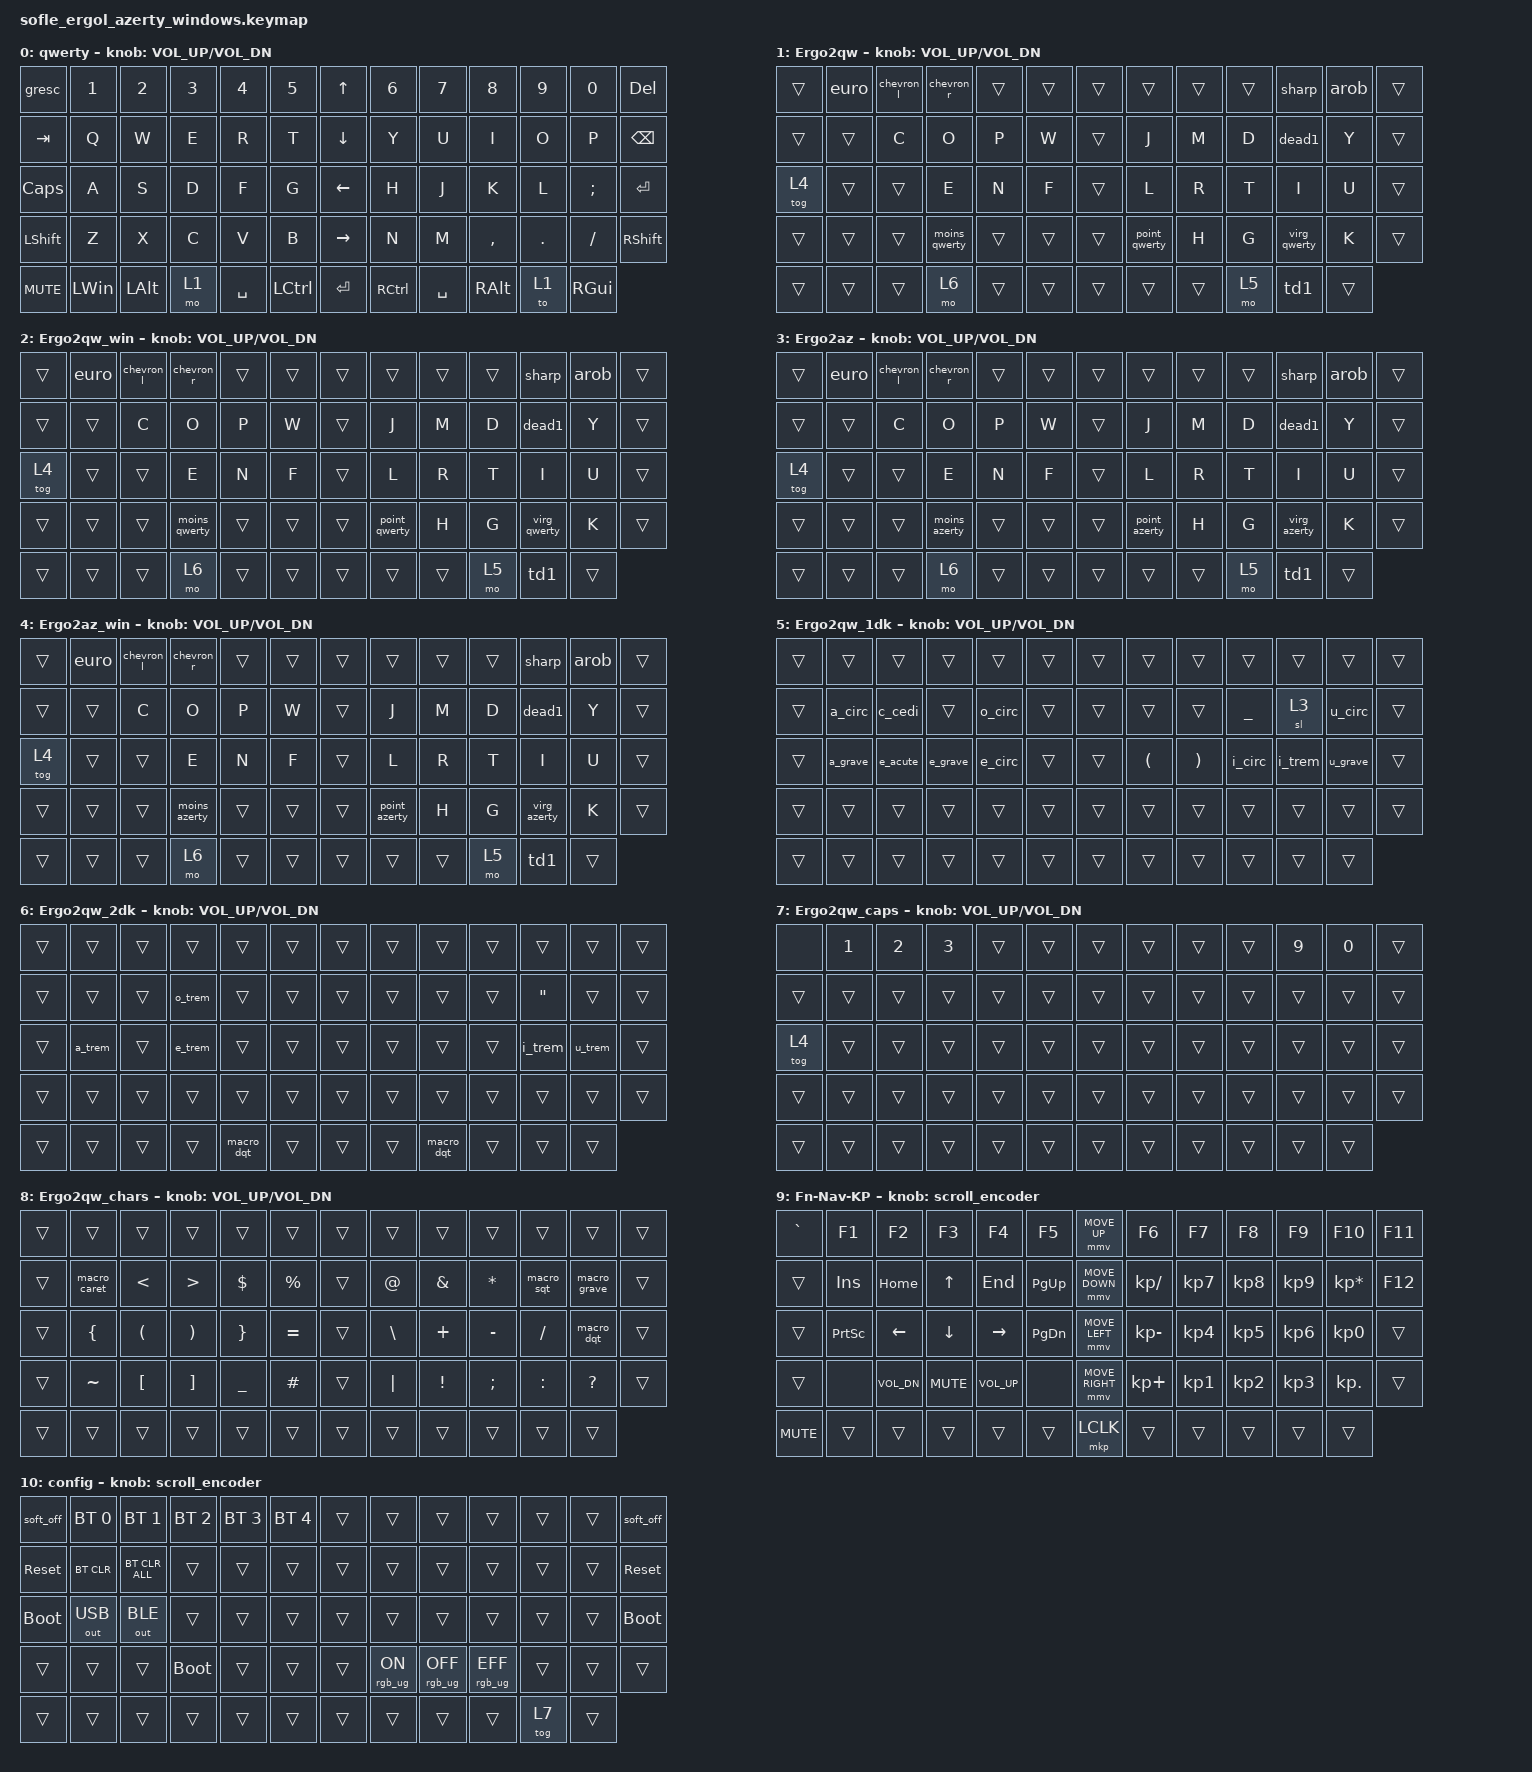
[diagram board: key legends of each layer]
#define ZMK_POINTING_DEFAULT_MOVE_VAL 1200  // 600
#define ZMK_POINTING_DEFAULT_SCRL_VAL 25    // 10

#include <input/processors.dtsi>
#include <zephyr/dt-bindings/input/input-event-codes.h>
#include <behaviors.dtsi>
#include <dt-bindings/zmk/bt.h>
#include <dt-bindings/zmk/keys.h>
#include <dt-bindings/zmk/outputs.h>
#include <dt-bindings/zmk/pointing.h>
#include <dt-bindings/zmk/rgb.h>

&mmv_input_listener { input-processors = <&zip_xy_scaler 2 1>; };

&msc_input_listener { input-processors = <&zip_scroll_scaler 2 1>; };

&msc {
    acceleration-exponent = <1>;      // 0
    time-to-max-speed-ms = <100>;       // 300
    delay-ms = <0>;                   // 0
};

&mmv {
    time-to-max-speed-ms = <500>;
    acceleration-exponent = <1>;
    trigger-period-ms = <16>;
};

/ {
    scroll_encoder: scroll_encoder {
        compatible = "zmk,behavior-sensor-rotate";
        #sensor-binding-cells = <0>;
        bindings = <&msc SCRL_DOWN>, <&msc SCRL_UP>;

        tap-ms = <100>;
    };

    macros {
        /////////////////////////////////////////////////////////////////////////////
        // Rangée 1                                                                //
        /////////////////////////////////////////////////////////////////////////////

        // ESC : QWERTY, AZERTY : ESC
        // ` : QWERTY : GRAVE
        // ` : AZERTY : BSLH SPACE
        macro_grave_azerty: macro_grave_azerty {
            compatible = "zmk,behavior-macro";
            #binding-cells = <0>;
            bindings
                = <&macro_tap &kp BSLH &kp SPACE>
                ;
        };
        // TRANS
        // TRANS
        // TRANS
        // TRANS

        ////// Normal //////
        // 1 : QWERTY : N1
        // 1 : AZERTY : LS(N1)
        ////// Shift //////
        // € : QWERTY : RA(N5)
        // € : AZERTY : RA(E) 
        ////// 1DK //////
        // „ : QWERTY, AZERTY : U+201E : Alt(0132) : DOUBLE LOW-9 QUOTATION MARK
        macro_dqt_low: macro_double_quote_low {
            compatible = "zmk,behavior-macro";
            #binding-cells = <0>;
            bindings
                = <&macro_press &kp L_CTL &kp L_SHIFT>
                , <&macro_tap &kp U &kp N2 &kp N0 &kp N1 &kp E &kp SPACE>
                , <&macro_release &kp L_CTL &kp L_SHIFT>
                ;
        };
        macro_dqt_low_win: macro_double_quote_low_win {
            compatible = "zmk,behavior-macro";
            #binding-cells = <0>;
            bindings
                = <&macro_press &kp L_ALT>
                , <&macro_tap &kp N0 &kp N1 &kp N3 &kp N2>
                , <&macro_release &kp L_ALT>
                ;
        };
        ////// 1DK Shift //////
        // NONE
        ////// Symboles //////
        // ₁ : QWERTY, AZERTY : U+2081 : SUBSCRIPT ONE
        macro_sub_1: macro_subscript_1 {
            compatible = "zmk,behavior-macro";
            #binding-cells = <0>;
            bindings
                = <&macro_press &kp L_CTL &kp L_SHIFT>
                , <&macro_tap &kp U &kp N2 &kp N0 &kp N8 &kp N1 &kp SPACE>
                , <&macro_release &kp L_CTL &kp L_SHIFT>
                ;
        };
        // ₁ : NO macro_sub_1_win : NONE
        ////// Symboles Shift //////
        // ¹ : QWERTY, AZERTY : U+00B9 : Alt(0185) : SUPERSCRIPT ONE
        macro_sup_1: macro_superscript_1 {
            compatible = "zmk,behavior-macro";
            #binding-cells = <0>;
            bindings
                = <&macro_press &kp L_CTL &kp L_SHIFT>
                , <&macro_tap &kp U &kp N0 &kp N0 &kp B &kp N9 &kp SPACE>
                , <&macro_release &kp L_CTL &kp L_SHIFT>
                ;
        };
        macro_sup_1_win: macro_superscript_1_win {
            compatible = "zmk,behavior-macro";
            #binding-cells = <0>;
            bindings
                = <&macro_press &kp L_ALT>
                , <&macro_tap &kp N0 &kp N1 &kp N8 &kp N5>
                , <&macro_release &kp L_ALT>
                ;
        };

        ////// Normal //////
        // 2 : QWERTY : N2
        // 2 : AZERTY : LS(N2)
        ////// Shift //////
        // « : QWERTY, AZERTY : U+00AB : Alt(0171) : LEFT-POINTING DOUBLE ANGLE QUOTATION MARK {left guillemet; chevrons (in typography)}
        macro_chevron_l: macro_chevron_left {
            compatible = "zmk,behavior-macro";
            #binding-cells = <0>;
            bindings
                = <&macro_press &kp L_CTL &kp L_SHIFT>
                , <&macro_tap &kp U &kp N0 &kp N0 &kp A &kp B &kp SPACE>
                , <&macro_release &kp L_CTL &kp L_SHIFT>
                ;
        };
        macro_chevron_l_win: macro_chevron_left_win {
            compatible = "zmk,behavior-macro";
            #binding-cells = <0>;
            bindings
                = <&macro_press &kp L_ALT>
                , <&macro_tap &kp N0 &kp N1 &kp N7 &kp N1>
                , <&macro_release &kp L_ALT>
                ;
        };
        ////// 1DK //////
        // “ : QWERTY, AZERTY : U+201C : Alt(0147) : LEFT DOUBLE QUOTATION MARK {double turned comma quotation mark}
        macro_dqm_l: macro_d_quot_mark_left {
            compatible = "zmk,behavior-macro";
            #binding-cells = <0>;
            bindings
                = <&macro_press &kp L_CTL &kp L_SHIFT>
                , <&macro_tap &kp U &kp N2 &kp N0 &kp N1 &kp C &kp SPACE>
                , <&macro_release &kp L_CTL &kp L_SHIFT>
                ;
        };
        macro_dqm_l_win: macro_d_quot_mark_left_win {
            compatible = "zmk,behavior-macro";
            #binding-cells = <0>;
            bindings
                = <&macro_press &kp L_ALT>
                , <&macro_tap &kp N0 &kp N1 &kp N4 &kp N7>
                , <&macro_release &kp L_ALT>
                ;
        };
        ////// 1DK Shift //////
        // ‘ : QWERTY, AZERTY : U+2018 : Alt(0145) : LEFT SINGLE QUOTATION MARK {single turned comma quotation mark}
        macro_sqm_l: macro_s_quot_mark_left {
            compatible = "zmk,behavior-macro";
            #binding-cells = <0>;
            bindings
                = <&macro_press &kp L_CTL &kp L_SHIFT>
                , <&macro_tap &kp U &kp N2 &kp N0 &kp N1 &kp N8 &kp SPACE>
                , <&macro_release &kp L_CTL &kp L_SHIFT>
                ;
        };
        macro_sqm_l_win: macro_s_quot_mark_left_win {
            compatible = "zmk,behavior-macro";
            #binding-cells = <0>;
            bindings
                = <&macro_press &kp L_ALT>
                , <&macro_tap &kp N0 &kp N1 &kp N4 &kp N5>
                , <&macro_release &kp L_ALT>
                ;
        };
        ////// Symboles //////
        // ₂ : QWERTY, AZERTY : U+2082 : SUBSCRIPT TWO
        macro_sub_2: macro_subscript_2 {
            compatible = "zmk,behavior-macro";
            #binding-cells = <0>;
            bindings
                = <&macro_press &kp L_CTL &kp L_SHIFT>
                , <&macro_tap &kp U &kp N2 &kp N0 &kp N8 &kp N2 &kp SPACE>
                , <&macro_release &kp L_CTL &kp L_SHIFT>
                ;
        };
        // ₂ : NO macro_sub_2_win : NONE
        ////// Symboles Shift //////
        // ² : QWERTY: RA(N2)
        // ² : AZERTY : GRAVE
    
        ////// Normal //////
        // 3 : QWERTY : N3
        // 3 : AZERTY : LS(N3)
        ////// Shift //////
        // » : QWERTY, AZERTY : U+00BB : Alt(0187) : RIGHT-POINTING DOUBLE ANGLE QUOTATION MARK {right guillemet}
        macro_chevron_r: macro_chevron_right {
            compatible = "zmk,behavior-macro";
            #binding-cells = <0>;
            bindings
                = <&macro_press &kp L_CTL &kp L_SHIFT>
                , <&macro_tap &kp U &kp N0 &kp N0 &kp B &kp B &kp SPACE>
                , <&macro_release &kp L_CTL &kp L_SHIFT>
                ;
        };
        macro_chevron_r_win: macro_chevron_right_win {
            compatible = "zmk,behavior-macro";
            #binding-cells = <0>;
            bindings
                = <&macro_press &kp L_ALT>
                , <&macro_tap &kp N0 &kp N1 &kp N8 &kp N7>
                , <&macro_release &kp L_ALT>
                ;
        };
        ////// 1DK //////
        // ” : QWERTY, AZERTY : U+201D : Alt(0148) : RIGHT DOUBLE QUOTATION MARK {double comma quotation mark}
        macro_dqm_r: macro_d_quot_mark_right {
            compatible = "zmk,behavior-macro";
            #binding-cells = <0>;
            bindings
                = <&macro_press &kp L_CTL &kp L_SHIFT>
                , <&macro_tap &kp U &kp N2 &kp N0 &kp N1 &kp D &kp SPACE>
                , <&macro_release &kp L_CTL &kp L_SHIFT>
                ;
        };
        macro_dqm_r_win: macro_d_quot_mark_right_win {
            compatible = "zmk,behavior-macro";
            #binding-cells = <0>;
            bindings
                = <&macro_press &kp L_ALT>
                , <&macro_tap &kp N0 &kp N1 &kp N4 &kp N8>
                , <&macro_release &kp L_ALT>
                ;
        };
        ////// 1DK Shift //////
        // ’ : QWERTY, AZERTY : U+2019 : Alt(0146) : RIGHT SINGLE QUOTATION MARK {single comma quotation mark}
        macro_sqm_r: macro_s_quot_mark_right {
            compatible = "zmk,behavior-macro";
            #binding-cells = <0>;
            bindings
                = <&macro_press &kp L_CTL &kp L_SHIFT>
                , <&macro_tap &kp U &kp N2 &kp N0 &kp N1 &kp N9 &kp SPACE>
                , <&macro_release &kp L_CTL &kp L_SHIFT>
                ;
        };
        macro_sqm_r_win: macro_s_quot_mark_right_win {
            compatible = "zmk,behavior-macro";
            #binding-cells = <0>;
            bindings
                = <&macro_press &kp L_ALT>
                , <&macro_tap &kp N0 &kp N1 &kp N4 &kp N6>
                , <&macro_release &kp L_ALT>
                ;
        };
        ////// Symboles //////
        // ₃ : QWERTY, AZERTY : U+2083 : SUBSCRIPT THREE
        macro_sub_3: macro_subscript_3 {
            compatible = "zmk,behavior-macro";
            #binding-cells = <0>;
            bindings
                = <&macro_press &kp L_CTL &kp L_SHIFT>
                , <&macro_tap &kp U &kp N2 &kp N0 &kp N8 &kp N3 &kp SPACE>
                , <&macro_release &kp L_CTL &kp L_SHIFT>
                ;
        };
        // ₃ : NO macro_sub_3_win : NONE
        ////// Symboles Shift //////
        // ³ : LS(GRAVE)
        // ² : RA(N3)
        

        ////// Normal //////
        // 4 : QWERTY : N4
        // 4 : AZERTY : LS(N4)
        ////// Shift //////
        // $ : QWERTY : DOLLAR
        // $ : AZERTY : RBKT
        ////// 1DK //////
        // ¢ : QWERTY, AZERTY : U+00A2 : Alt(0162) : CENT SIGN
        macro_cent: macro_cent {
            compatible = "zmk,behavior-macro";
            #binding-cells = <0>;
            bindings
                = <&macro_press &kp L_CTL &kp L_SHIFT>
                , <&macro_tap &kp U &kp N0 &kp N0 &kp A &kp N2 &kp SPACE>
                , <&macro_release &kp L_CTL &kp L_SHIFT>
                ;
        }; 
        macro_cent_win: macro_cent_win {
            compatible = "zmk,behavior-macro";
            #binding-cells = <0>;
            bindings
                = <&macro_press &kp L_ALT>
                , <&macro_tap &kp N0 &kp N1 &kp N6 &kp N2>
                , <&macro_release &kp L_ALT>
                ;
        }; 
        ////// 1DK Shift //////
        // NONE
        ////// Symboles //////
        // ₄ : QWERTY, AZERTY : U+2084 : SUBSCRIPT FOUR
        macro_sub_4: macro_subscript_4 {
            compatible = "zmk,behavior-macro";
            #binding-cells = <0>;
            bindings
                = <&macro_press &kp L_CTL &kp L_SHIFT>
                , <&macro_tap &kp U &kp N2 &kp N0 &kp N8 &kp N4 &kp SPACE>
                , <&macro_release &kp L_CTL &kp L_SHIFT>
                ;
        };
        // ₄ : NO macro_sub_4_win : NONE
        ////// Symboles Shift //////
        // ⁴ : QWERTY, AZERTY : U+2074 : SUPERSCRIPT FOUR
        macro_sup_4: macro_superscript_4 {
            compatible = "zmk,behavior-macro";
            #binding-cells = <0>;
            bindings
                = <&macro_press &kp L_CTL &kp L_SHIFT>
                , <&macro_tap &kp U &kp N2 &kp N0 &kp N7 &kp N4 &kp SPACE>
                , <&macro_release &kp L_CTL &kp L_SHIFT>
                ;
        };
        // ⁴ : NO macro_sup_4_win : NONE


        ////// Normal //////
        // 5 : QWERTY : N5
        // 5 : AZERTY : LS(N5)
        ////// Shift //////
        // % : QWERTY : LS(N5)
        // % : AZERTY : DQT
        ////// 1DK //////
        // ‰ : QWERTY, AZERTY : U+2030 : Alt(0137) : PER MILLE SIGN {permille, per thousand}
        macro_mer_mil: macro_pour_mille {
            compatible = "zmk,behavior-macro";
            #binding-cells = <0>;
            bindings
                = <&macro_press &kp L_CTL &kp L_SHIFT>
                , <&macro_tap &kp U &kp N2 &kp N0 &kp N3 &kp N0 &kp SPACE>
                , <&macro_release &kp L_CTL &kp L_SHIFT>
                ;
        };
        macro_mer_mil_win: macro_pour_mille_win {
            compatible = "zmk,behavior-macro";
            #binding-cells = <0>;
            bindings
                = <&macro_press &kp L_ALT>
                , <&macro_tap &kp N0 &kp N1 &kp N3 &kp N7>
                , <&macro_release &kp L_ALT>
                ;
        };
        ////// 1DK Shift //////
        // NONE
        ////// Symboles //////
        // ₅ : QWERTY, AZERTY : U+2085 : SUBSCRIPT FIVE
        macro_sub_5: macro_subscript_5 {
            compatible = "zmk,behavior-macro";
            #binding-cells = <0>;
            bindings
                = <&macro_press &kp L_CTL &kp L_SHIFT>
                , <&macro_tap &kp U &kp N2 &kp N0 &kp N8 &kp N5 &kp SPACE>
                , <&macro_release &kp L_CTL &kp L_SHIFT>
                ;
        };
        // ₅ : NO macro_sub_5_win : NONE
        ////// Symboles Shift //////
        // ⁵ : QWERTY, AZERTY : U+2075 : SUPERSCRIPT FIVE
        macro_sup_5: macro_superscript_5 {
            compatible = "zmk,behavior-macro";
            #binding-cells = <0>;
            bindings
                = <&macro_press &kp L_CTL &kp L_SHIFT>
                , <&macro_tap &kp U &kp N2 &kp N0 &kp N7 &kp N5 &kp SPACE>
                , <&macro_release &kp L_CTL &kp L_SHIFT>
                ;
        };
        // ⁵ : NO macro_sup_5_win : NONE


        ////// Normal //////
        // 6 : QWERTY : N6
        // 6 : AZERTY : LS(N6)
        ////// Shift //////
        // ^ : QWERTY : LS(N6)
        // ^ : AZERTY : LBKT SPACE
        macro_caret_azerty: macro_caret_azerty {
            compatible = "zmk,behavior-macro";
            #binding-cells = <0>;
            bindings
                = <&macro_tap &kp LBKT &kp SPACE>
                ;
        };
        ////// 1DK //////
        // NONE
        ////// 1DK Shift //////
        // NONE
        ////// Symboles //////
        // ₆ : QWERTY, AZERTY : U+2086 : SUBSCRIPT SIX
        macro_sub_6: macro_subscript_6 {
            compatible = "zmk,behavior-macro";
            #binding-cells = <0>;
            bindings
                = <&macro_press &kp L_CTL &kp L_SHIFT>
                , <&macro_tap &kp U &kp N2 &kp N0 &kp N8 &kp N6 &kp SPACE>
                , <&macro_release &kp L_CTL &kp L_SHIFT>
                ;
        };
        // ₆ : NO macro_sub_6_win : NONE
        ////// Symboles Shift //////
        // ⁶ : QWERTY, AZERTY : U+2076 : SUPERSCRIPT SIX
        macro_sup_6: macro_superscript_6 {
            compatible = "zmk,behavior-macro";
            #binding-cells = <0>;
            bindings
                = <&macro_press &kp L_CTL &kp L_SHIFT>
                , <&macro_tap &kp U &kp N2 &kp N0 &kp N7 &kp N6 &kp SPACE>
                , <&macro_release &kp L_CTL &kp L_SHIFT>
                ;
        };
        // ⁶ : NO macro_sup_6_win : NONE
       
        ////// Normal //////
        // 7 : QWERTY : N7
        // 7 : AZERTY : LS(N7)
        ////// Shift //////
        // & : QWERTY : LS(N7)
        // & : AZERTY : N7
        ////// 1DK //////
        // NONE
        ////// 1DK Shift //////
        // NONE
        ////// Symboles //////
        // ₇ : QWERTY, AZERTY : U+2087 : SUBSCRIPT SEVEN
        macro_sub_7: macro_subscript_7 {
            compatible = "zmk,behavior-macro";
            #binding-cells = <0>;
            bindings
                = <&macro_press &kp L_CTL &kp L_SHIFT>
                , <&macro_tap &kp U &kp N2 &kp N0 &kp N8 &kp N7 &kp SPACE>
                , <&macro_release &kp L_CTL &kp L_SHIFT>
                ;
        };
        // ₇ : NO macro_sub_7_win : NONE
        ////// Symboles Shift //////
        // ⁷ : QWERTY, AZERTY : U+2077 : SUPERSCRIPT SEVEN
        macro_sup_7: macro_superscript_7 {
            compatible = "zmk,behavior-macro";
            #binding-cells = <0>;
            bindings
                = <&macro_press &kp L_CTL &kp L_SHIFT>
                , <&macro_tap &kp U &kp N2 &kp N0 &kp N7 &kp N7 &kp SPACE>
                , <&macro_release &kp L_CTL &kp L_SHIFT>
                ;
        };
        // ⁷ : NO macro_sup_7_win : NONE

        ////// Normal //////
        // 8 : QWERTY : N8
        // 8 : AZERTY : LS(N8)
        ////// Shift //////
        // * : QWERTY : LS(N8)
        // * : AZERTY : N8
        ////// 1DK //////
        // NONE
        ////// 1DK Shift //////
        // NONE
        ////// Symboles //////
        // ₈ : QWERTY, AZERTY : U+2088 : SUBSCRIPT EIGHT
        macro_sub_8: macro_subscript_8 {
            compatible = "zmk,behavior-macro";
            #binding-cells = <0>;
            bindings
                = <&macro_press &kp L_CTL &kp L_SHIFT>
                , <&macro_tap &kp U &kp N2 &kp N0 &kp N8 &kp N8 &kp SPACE>
                , <&macro_release &kp L_CTL &kp L_SHIFT>
                ;
        };
        // ₈ : NO macro_sub_8_win : NONE
        ////// Symboles Shift //////
        // ⁸ : QWERTY, AZERTY : U+2078 : SUPERSCRIPT EIGHT
        macro_sup_8: macro_superscript_8 {
            compatible = "zmk,behavior-macro";
            #binding-cells = <0>;
            bindings
                = <&macro_press &kp L_CTL &kp L_SHIFT>
                , <&macro_tap &kp U &kp N2 &kp N0 &kp N7 &kp N8 &kp SPACE>
                , <&macro_release &kp L_CTL &kp L_SHIFT>
                ;
        };
        // ⁸ : NO macro_sup_8_win : NONE

        ////// Normal //////
        // 9 : QWERTY : N9
        // 9 : AZERTY : LS(N9)
        ////// Shift //////
        // # : QWERTY : LS(N3)
        // # : AZERTY : RA(N3)
        ////// 1DK //////
        // ¶ : QWERTY, AZERTY : U+00B6 : Alt(0182) : PILCROW SIGN {paragraph sign}
        macro_pilcrow: macro_pilcrow {
            compatible = "zmk,behavior-macro";
            #binding-cells = <0>;
            bindings
                = <&macro_press &kp L_CTL &kp L_SHIFT>
                , <&macro_tap &kp U &kp N0 &kp N0 &kp B &kp N6 &kp SPACE>
                , <&macro_release &kp L_CTL &kp L_SHIFT>
                ;
        };
        macro_pilcrow_win: macro_pilcrow_win {
            compatible = "zmk,behavior-macro";
            #binding-cells = <0>;
            bindings
                = <&macro_press &kp L_ALT>
                , <&macro_tap &kp N0 &kp N1 &kp N8 &kp N2>
                , <&macro_release &kp L_ALT>
                ;
        };
        ////// 1DK Shift //////
        // NONE
        ////// Symboles //////
        // ₉ : QWERTY, AZERTY : U+2089 : SUBSCRIPT NINE
        macro_sub_9: macro_subscript_9 {
            compatible = "zmk,behavior-macro";
            #binding-cells = <0>;
            bindings
                = <&macro_press &kp L_CTL &kp L_SHIFT>
                , <&macro_tap &kp U &kp N2 &kp N0 &kp N8 &kp N9 &kp SPACE>
                , <&macro_release &kp L_CTL &kp L_SHIFT>
                ;
        };
        // ₉ : NO macro_sub_9_win : NONE
        ////// Symboles Shift //////
        // ⁹ : QWERTY, AZERTY : U+2079 : SUPERSCRIPT NINE
        macro_sup_9: macro_superscript_9 {
            compatible = "zmk,behavior-macro";
            #binding-cells = <0>;
            bindings
                = <&macro_press &kp L_CTL &kp L_SHIFT>
                , <&macro_tap &kp U &kp N2 &kp N0 &kp N7 &kp N9 &kp SPACE>
                , <&macro_release &kp L_CTL &kp L_SHIFT>
                ;
        };
        // ⁹ : NO macro_sup_9_win : NONE


        ////// Normal //////
        // 0 : QWERTY : N0
        // 0 : AZERTY : LS(N0)
        ////// Shift //////
        // @ : QWERTY : LS(N2)
        // @ : AZERTY : RA(Q)
        ////// 1DK //////
        // ° : QWERTY : U+00B0 : Alt(0176) : DEGREE SIGN
        macro_degree_qwerty: macro_degree_qwerty {
            compatible = "zmk,behavior-macro";
            #binding-cells = <0>;
            bindings
                = <&macro_press &kp L_CTL &kp L_SHIFT>
                , <&macro_tap &kp U &kp N0 &kp N0 &kp B &kp N0 &kp SPACE>
                , <&macro_release &kp L_CTL &kp L_SHIFT>
                ;
        };
        macro_degree_qwerty_win: macro_degree_win {
            compatible = "zmk,behavior-macro";
            #binding-cells = <0>;
            bindings
                = <&macro_press &kp L_ALT>
                , <&macro_tap &kp N0 &kp N1 &kp N7 &kp N6>
                , <&macro_release &kp L_ALT>
                ;
        };
        // ° : AZERTY : LS(MINUS)
        ////// 1DK Shift //////
        // NONE
        ////// Symboles //////
        // ₀ : QWERTY, AZERTY : U+2080 : SUBSCRIPT ZERO
        macro_sub_0: macro_subscript_0 {
            compatible = "zmk,behavior-macro";
            #binding-cells = <0>;
            bindings
                = <&macro_press &kp L_CTL &kp L_SHIFT>
                , <&macro_tap &kp U &kp N2 &kp N0 &kp N8 &kp N0 &kp SPACE>
                , <&macro_release &kp L_CTL &kp L_SHIFT>
                ;
        };
        // ₀ : NO macro_sub_0_win : NONE
        ////// Symboles Shift //////
        // ⁰ : QWERTY, AZERTY : U+2070 : SUPERSCRIPT ZERO
        macro_sup_0: macro_superscript_0 {
            compatible = "zmk,behavior-macro";
            #binding-cells = <0>;
            bindings
                = <&macro_press &kp L_CTL &kp L_SHIFT>
                , <&macro_tap &kp U &kp N2 &kp N0 &kp N7 &kp N0 &kp SPACE>
                , <&macro_release &kp L_CTL &kp L_SHIFT>
                ;
        };
        // ⁰ : NO macro_sup_0_win : NONE
        

        // DELETE
        // TRANS
        // TRANS
        // TRANS
        // TRANS

 
        /////////////////////////////////////////////////////////////////////////////
        // Rangée 2                                                                //
        /////////////////////////////////////////////////////////////////////////////

        // TAB
        // TRANS
        // TRANS ?
        // TRANS ?

        ////// Normal et Shift //////
        // Q : QWERTY : Q
        // Q : AZERTY : A
        ////// 1DK //////
        // â : QWERTY, AZERTY : U+00E2 : Alt(0226) : LATIN SMALL LETTER A WITH CIRCUMFLEX
        macro_a_circ: macro_a_circ {
            compatible = "zmk,behavior-macro";
            #binding-cells = <0>;
            bindings
                = <&macro_press &kp L_CTL &kp L_SHIFT>
                , <&macro_tap &kp U &kp N0 &kp N0 &kp E &kp N2 &kp SPACE>
                , <&macro_release &kp L_CTL &kp L_SHIFT>
                ;
        };
        macro_a_circ_win: macro_a_circ_win {
            compatible = "zmk,behavior-macro";
            #binding-cells = <0>;
            bindings
                = <&macro_press &kp L_ALT>
                , <&macro_tap &kp N0 &kp N2 &kp N2 &kp N6>
                , <&macro_release &kp L_ALT>
                ;
        };  
        ////// 1DK Shift //////
        // Â : QWERTY, AZERTY : U+00C2 : Alt(0194) : LATIN CAPITAL LETTER A WITH CIRCUMFLEX
        macro_cap_a_circ: macro_cap_a_circ {
            compatible = "zmk,behavior-macro";
            #binding-cells = <0>;
            bindings
                = <&macro_press &kp L_CTL &kp L_SHIFT>
                , <&macro_tap &kp U &kp N0 &kp N0 &kp C &kp N2 &kp SPACE>
                , <&macro_release &kp L_CTL &kp L_SHIFT>
                ;
        };
        macro_cap_a_circ_win: macro_cap_a_circ_win {
            compatible = "zmk,behavior-macro";
            #binding-cells = <0>;
            bindings
                = <&macro_press &kp L_ALT>
                , <&macro_tap &kp N0 &kp N1 &kp N9 &kp N4>
                , <&macro_release &kp L_ALT>
                ;
        };
        ////// Symboles //////
        // ^ : QWERTY : LS(N6) SPACE
        macro_caret_qwerty: macro_caret_qwerty {
            compatible = "zmk,behavior-macro";
            #binding-cells = <0>;
            bindings
                = <&macro_tap &kp LS(N6) &kp SPACE>
                ;
        };
        // ^ : AZERTY : LBKT SPACE
        macro_caret_azerty: macro_caret_azerty {
            compatible = "zmk,behavior-macro";
            #binding-cells = <0>;
            bindings
                = <&macro_tap &kp LBKT &kp SPACE>
                ;
        };
        ////// Symboles Shift //////
        // ^ (MODIFIER) : QWERTY : LS(N6) 
        // ^ (MODIFIER) : AZERTY : LBKT 


        ////// Normal et Shift //////
        // C : QWERTY, AZERTY : C
        ////// 1DK //////
        // ç : QWERTY : U+00E7 : Alt(0231) : LATIN SMALL LETTER C WITH CEDILLA
        macro_c_cedi_qwerty: macro_c_cedille_qwerty {
            compatible = "zmk,behavior-macro";
            #binding-cells = <0>;
            bindings
                = <&macro_press &kp L_CTL &kp L_SHIFT>
                , <&macro_tap &kp U &kp N0 &kp N0 &kp E &kp N7 &kp SPACE>
                , <&macro_release &kp L_CTL &kp L_SHIFT>
                ;
        };
        macro_c_cedi_qwerty_win: macro_c_cedille_qwerty_win {
            compatible = "zmk,behavior-macro";
            #binding-cells = <0>;
            bindings
                = <&macro_press &kp L_ALT>
                , <&macro_tap &kp N0 &kp N2 &kp N3 &kp N1>
                , <&macro_release &kp L_ALT>
                ;
        };  
        // ç : AZERTY : N9
        ////// 1DK Shift //////
        // Ç : QWERTY : U+00C7 : Alt(0199) : LATIN CAPITAL LETTER C WITH CEDILLA
        macro_cap_c_cedi_qwerty: macro_cap_c_cedille_qwerty {
            compatible = "zmk,behavior-macro";
            #binding-cells = <0>;
            bindings
                = <&macro_press &kp L_CTL &kp L_SHIFT>
                , <&macro_tap &kp U &kp N0 &kp N0 &kp C &kp N7 &kp SPACE>
                , <&macro_release &kp L_CTL &kp L_SHIFT>
                ;
        };
        macro_cap_c_cedi_qwerty_win: macro_cap_c_cedille_qwerty_win {
            compatible = "zmk,behavior-macro";
            #binding-cells = <0>;
            bindings
                = <&macro_press &kp L_ALT>
                , <&macro_tap &kp N0 &kp N1 &kp N9 &kp N9>
                , <&macro_release &kp L_ALT>
                ;
        };  
        // Ç : AZERTY : U+00C7 : LATIN CAPITAL LETTER C WITH CEDILLA
        macro_cap_c_cedi_azerty: macro_cap_c_cedille_azerty {
            compatible = "zmk,behavior-macro";
            #binding-cells = <0>;
            bindings
                = <&macro_press &kp L_CTL &kp L_SHIFT>
                , <&macro_tap &kp U &kp N0 &kp N0 &kp C &kp N7 &kp SPACE>
                , <&macro_release &kp L_CTL &kp L_SHIFT>
                ;
        };
        // Ç : AZERTY : Alt(0199) : LATIN CAPITAL LETTER C WITH CEDILLA
        macro_cap_c_cedi_azerty_win: macro_cap_c_cedille_azerty_win {
            compatible = "zmk,behavior-macro";
            #binding-cells = <0>;
            bindings
                = <&macro_press &kp L_ALT>
                , <&macro_tap &kp N0 &kp N1 &kp N9 &kp N9>
                , <&macro_release &kp L_ALT>
                ;
        };
        ////// Symboles //////
        // < : QWERTY : LESS_THAN
        // < : AZERTY : BSLH
        ////// Symboles Shift //////
        // ≤ : QWERTY, AZERTY : U+2264 : LESS-THAN OR EQUAL TO
        macro_less_eq_to: macro_less_equal_to {
            compatible = "zmk,behavior-macro";
            #binding-cells = <0>;
            bindings
                = <&macro_press &kp L_CTL &kp L_SHIFT>
                , <&macro_tap &kp U &kp N2 &kp N2 &kp N6 &kp N4 &kp SPACE>
                , <&macro_release &kp L_CTL &kp L_SHIFT>
                ;
        };
        // ≤ : NO macro_less_eq_to_win : NONE


        ////// Normal et Shift //////
        // O : QWERTY, AZERTY : O
        ////// 1DK //////
        // œ : QWERTY, AZERTY : U+0153 : LATIN SMALL LIGATURE OE {ethel (from Old English eðel)}
        macro_o_e: macro_o_e {
            compatible = "zmk,behavior-macro";
            #binding-cells = <0>;
            bindings
                = <&macro_press &kp L_CTL &kp L_SHIFT>
                , <&macro_tap &kp U &kp N0 &kp N1 &kp N5 &kp N3 &kp SPACE>
                , <&macro_release &kp L_CTL &kp L_SHIFT>
                ;
        };
        // œ : QWERTY, AZERTY : Alt(0156) : LATIN SMALL LIGATURE OE {ethel (from Old English eðel)}
        macro_o_e_win: macro_o_e_win {
            compatible = "zmk,behavior-macro";
            #binding-cells = <0>;
            bindings
                = <&macro_press &kp L_ALT>
                , <&macro_tap &kp N0 &kp N1 &kp N5 &kp N6>
                , <&macro_release &kp L_ALT>
                ;
        };
        ////// 1DK Shift //////
        // Œ : QWERTY, AZERTY : U+0152 : LATIN CAPITAL LIGATURE OE
        macro_cap_o_e: macro_cap_o_e {
            compatible = "zmk,behavior-macro";
            #binding-cells = <0>;
            bindings
                = <&macro_press &kp L_CTL &kp L_SHIFT>
                , <&macro_tap &kp U &kp N0 &kp N1 &kp N5 &kp N2 &kp SPACE>
                , <&macro_release &kp L_CTL &kp L_SHIFT>
                ;
        };
        // Œ : QWERTY, AZERTY : Alt(0140) : LATIN CAPITAL LIGATURE OE
        macro_cap_o_e_win: macro_cap_o_e_win {
            compatible = "zmk,behavior-macro";
            #binding-cells = <0>;
            bindings
                = <&macro_press &kp L_ALT>
                , <&macro_tap &kp N0 &kp N1 &kp N4 &kp N0>
                , <&macro_release &kp L_ALT>
                ;
        };
        ////// Symboles //////
        // > : QWERTY : GREATER_THAN
        // > : AZERTY : PIPE
        ////// Symboles Shift //////
        // ≥ : QWERTY, AZERTY : U+2265 : GREATER-THAN OR EQUAL TO
        macro_great_eq_to: macro_greater_equal_to {
            compatible = "zmk,behavior-macro";
            #binding-cells = <0>;
            bindings
                = <&macro_press &kp L_CTL &kp L_SHIFT>
                , <&macro_tap &kp U &kp N2 &kp N2 &kp N6 &kp N5 &kp SPACE>
                , <&macro_release &kp L_CTL &kp L_SHIFT>
                ;
        };
        // ≥ : NO macro_great_eq_to_win : NONE


        ////// Normal et Shift //////
        // P : QWERTY, AZERTY : P
        ////// 1DK //////
        // ô : QWERTY, AZERTY : U+00F4 : Alt(0244) : LATIN SMALL LETTER O WITH CIRCUMFLEX
        macro_o_circ: macro_o_circonflexe {
            compatible = "zmk,behavior-macro";
            #binding-cells = <0>;
            bindings
                = <&macro_press &kp L_CTL &kp L_SHIFT>
                , <&macro_tap &kp U &kp N0 &kp N0 &kp F &kp N4 &kp SPACE>
                , <&macro_release &kp L_CTL &kp L_SHIFT>
                ;
        };
        macro_o_circ_win: macro_o_circonflexe_win {
            compatible = "zmk,behavior-macro";
            #binding-cells = <0>;
            bindings
                = <&macro_press &kp L_ALT>
                , <&macro_tap &kp N0 &kp N2 &kp N4 &kp N4>
                , <&macro_release &kp L_ALT>
                ;
        };  
        ////// 1DK Shift //////
        // Ô : QWERTY, AZERTY : U+00D4 : Alt(0212) : LATIN CAPITAL LETTER O WITH CIRCUMFLEX
        macro_cap_o_circ: macro_cap_o_circonflexe {
            compatible = "zmk,behavior-macro";
            #binding-cells = <0>;
            bindings
                = <&macro_press &kp L_CTL &kp L_SHIFT>
                , <&macro_tap &kp U &kp N0 &kp N0 &kp D &kp N4 &kp SPACE>
                , <&macro_release &kp L_CTL &kp L_SHIFT>
                ;
        };
        macro_cap_o_circ_win: macro_cap_o_circonflexe_win {
            compatible = "zmk,behavior-macro";
            #binding-cells = <0>;
            bindings
                = <&macro_press &kp L_ALT>
                , <&macro_tap &kp N0 &kp N2 &kp N1 &kp N2>
                , <&macro_release &kp L_ALT>
                ;
        };  
        ////// Symboles //////
        // $ : QWERTY : DOLLAR
        // $ : AZERTY : RBKT
        ////// Symboles Shift //////
        // ¤ : TODO CURRENCY LAYER TOGGLE : NONE


        ////// Normal et Shift //////
        // W : QWERTY : W
        // W : AZERTY : Z
        ////// 1DK //////
        // NONE
        ////// 1DK Shift //////
        // NONE
        ////// Symboles //////
        // % : QWERTY : PERCENT
        // % : AZERTY : LS(SQT)
        ////// Symboles Shift //////
        // ‰ : QWERTY, AZERTY : U+2030 : PER MILLE SIGN {permille, per thousand}
        macro_per_mil: macro_per_mille {
            compatible = "zmk,behavior-macro";
            #binding-cells = <0>;
            bindings
                = <&macro_press &kp L_CTL &kp L_SHIFT>
                , <&macro_tap &kp U &kp N2 &kp N0 &kp N3 &kp N0 &kp SPACE>
                , <&macro_release &kp L_CTL &kp L_SHIFT>
                ;
        };
        // ‰ : QWERTY, AZERTY : Alt(0137) : PER MILLE SIGN {permille, per thousand}
        macro_per_mil_win: macro_per_mille_win {
            compatible = "zmk,behavior-macro";
            #binding-cells = <0>;
            bindings
                = <&macro_press &kp L_ALT>
                , <&macro_tap &kp N0 &kp N1 &kp N3 &kp N7>
                , <&macro_release &kp L_ALT>
                ;
        };

        ////// Normal et Shift //////
        // J : QWERTY, AZERTY : J
        ////// 1DK //////
        // NONE
        ////// 1DK Shift //////
        // NONE
        ////// Symboles //////
        // @ : QWERTY : AT
        // @ : AZERTY : RA(N0)
        ////// Symboles Shift //////
        // ° : TODO ACCENT ROND LAYER TOG 

        ////// Normal et Shift //////
        // M : QWERTY : M
        // M : AZERTY : SEMI
        ////// 1DK //////
        // µ : QWERTY, AZERTY : U+00B5 : MICRO SIGN
        macro_micro: macro_micro {
            compatible = "zmk,behavior-macro";
            #binding-cells = <0>;
            bindings
                = <&macro_press &kp L_CTL &kp L_SHIFT>
                , <&macro_tap &kp U &kp N0 &kp N0 &kp B &kp N5 &kp SPACE>
                , <&macro_release &kp L_CTL &kp L_SHIFT>
                ;
        };
        // µ : QWERTY, AZERTY : Alt(0230) : MICRO SIGN
        macro_micro_win: macro_micro_win {
            compatible = "zmk,behavior-macro";
            #binding-cells = <0>;
            bindings
                = <&macro_press &kp L_ALT>
                , <&macro_tap &kp N0 &kp N2 &kp N3 &kp N0>
                , <&macro_release &kp L_ALT>
                ;
        };
        ////// 1DK Shift //////
        // NONE
        ////// Symboles //////
        // & : QWERTY : AMPS
        // & : AZERTY : N1
        ////// Symboles Shift //////
        // NONE


        ////// Normal et Shift //////
        // D : QWERTY, AZERTY : D
        ////// 1DK //////
        // _ : QWERTY : UNDER
        // _ : AZERTY : N8
        ////// 1DK Shift //////
        // _ : QWERTY : UNDER
        // _ : AZERTY : N8
        ////// Symboles //////
        // * : QWERTY : STAR
        // * : AZERTY : PIPE
        ////// Symboles Shift //////
        // × : QWERTY, AZERTY : U+00D7 : MULTIPLICATION SIGN {z notation Cartesian product}
        macro_multiply: macro_multiply {
            compatible = "zmk,behavior-macro";
            #binding-cells = <0>;
            bindings
                = <&macro_press &kp L_CTL &kp L_SHIFT>
                , <&macro_tap &kp U &kp N0 &kp N0 &kp D &kp N7 &kp SPACE>
                , <&macro_release &kp L_CTL &kp L_SHIFT>
                ;
        };
        // × : QWERTY, AZERTY : Alt(0215) : MULTIPLICATION SIGN {z notation Cartesian product}
        macro_multiply_win: macro_multiply_win {
            compatible = "zmk,behavior-macro";
            #binding-cells = <0>;
            bindings
                = <&macro_press &kp L_ALT>
                , <&macro_tap &kp N0 &kp N2 &kp N1 &kp N5>
                , <&macro_release &kp L_ALT>
                ;
        };

        ////// Normal //////
        // 1DK : sticky layer 1DK
        ////// Shift //////
        // ! : QWERTY : EXCL
        // ! : AZERTY : N8
        ////// 1DK //////
        // 2DK : " : QWERTY : DQT
        // 2DK : " : AZERTY : LBRC
        ////// 1DK Shift //////
        // ¡ : QWERTY, AZERTY : U+00A1 : INVERTED EXCLAMATION MARK
        macro_inv_excl: macro_inv_excl {
            compatible = "zmk,behavior-macro";
            #binding-cells = <0>;
            bindings
                = <&macro_press &kp L_CTL &kp L_SHIFT>
                , <&macro_tap &kp U &kp N0 &kp N0 &kp A &kp N1 &kp SPACE>
                , <&macro_release &kp L_CTL &kp L_SHIFT>
                ;
        // ¡ : QWERTY, AZERTY : Alt(173) : INVERTED EXCLAMATION MARK
        macro_inv_excl_win: macro_inv_excl_win {
            compatible = "zmk,behavior-macro";
            #binding-cells = <0>;
            bindings
                = <&macro_press &kp L_ALT>
                , <&macro_tap &kp N0 &kp N1 &kp N7 &kp N3>
                , <&macro_release &kp L_ALT>
                ;
        };
        ////// Symboles //////
        // ' : QWERTY : SQT SPACE
        // ' : AZERTY : N4
        ////// Symboles Shift //////
        // ' MODIFIER ACUTE : QWERTY :: SQT
        // ' MODIFIER ACUTE : AZERTY : TODO MODIFIER ACUTE : NONE 


        ////// Normal et Shift //////
        // Y : QWERTY, AZERTY : Y
        ////// 1DK //////
        // û : QWERTY, AZERTY : U+00FB : Alt(0251) : LATIN SMALL LETTER U WITH CIRCUMFLEX
        macro_u_circ: macro_u_circonflexe {
            compatible = "zmk,behavior-macro";
            #binding-cells = <0>;
            bindings
                = <&macro_press &kp L_CTL &kp L_SHIFT>
                , <&macro_tap &kp U &kp N0 &kp N0 &kp F &kp B &kp SPACE>
                , <&macro_release &kp L_CTL &kp L_SHIFT>
                ;
        };
        macro_u_circ_win: macro_u_circonflexe_win {
            compatible = "zmk,behavior-macro";
            #binding-cells = <0>;
            bindings
                = <&macro_press &kp L_ALT>
                , <&macro_tap &kp N0 &kp N2 &kp N5 &kp N1>
                , <&macro_release &kp L_ALT>
                ;
        };  
        ////// 1DK Shift //////
        // Û : QWERTY, AZERTY : U+00DB : Alt(0219) : LATIN CAPITAL LETTER U WITH CIRCUMFLEX
        macro_cap_u_circ: macro_cap_u_circonflexe {
            compatible = "zmk,behavior-macro";
            #binding-cells = <0>;
            bindings
                = <&macro_press &kp L_CTL &kp L_SHIFT>
                , <&macro_tap &kp U &kp N0 &kp N0 &kp D &kp B &kp SPACE>
                , <&macro_release &kp L_CTL &kp L_SHIFT>
                ;
        };
        macro_cap_u_circ_win: macro_cap_u_circonflexe_win {
            compatible = "zmk,behavior-macro";
            #binding-cells = <0>;
            bindings
                = <&macro_press &kp L_ALT>
                , <&macro_tap &kp N0 &kp N2 &kp N1 &kp N9>
                , <&macro_release &kp L_ALT>
                ;
        };  
        ////// Symboles //////
        // ` : QWERTY : GRAVE
        // ` : AZERTY : macro_grave_azerty : voir touche ESC
        ////// Symboles Shift //////
        // ` (MODIFIER) : QWERTY : TODO GRAVE MODIFIER LAYER TOGGLE
        // ` (MODIFIER) : AZERTY : RA(BSLH) 


        // BACKSPACE
        // TOGGLE 1DK
        // TOGGLE 2DK
        // TRANS
        // TRANS


        /////////////////////////////////////////////////////////////////////////////
        // Rangée 3                                                                //
        /////////////////////////////////////////////////////////////////////////////

        // CAPS
        // TRANS
        // TRANS
        // TRANS
        // TRANS


        ////// Normal et Shift //////
        // A : QWERTY : A
        // A : AZERTY : Q
        ////// 1DK //////
        // à : QWERTY : U+00E0 : Alt(0224) : LATIN SMALL LETTER A WITH GRAVE
        macro_a_grave_qwerty: macro_a_grave_qwerty {
            compatible = "zmk,behavior-macro";
            #binding-cells = <0>;
            bindings
                = <&macro_press &kp L_CTL &kp L_SHIFT>
                , <&macro_tap &kp U &kp N0 &kp N0 &kp E &kp N0 &kp SPACE>
                , <&macro_release &kp L_CTL &kp L_SHIFT>
                ;
        };
        macro_a_grave_qwerty_win: macro_a_grave_qwerty_win {
            compatible = "zmk,behavior-macro";
            #binding-cells = <0>;
            bindings
                = <&macro_press &kp L_ALT>
                , <&macro_tap &kp N0 &kp N2 &kp N2 &kp N4>
                , <&macro_release &kp L_ALT>
                ;
        };  
        // à : AZERTY : N0
        ////// 1DK Shift //////
        // À : QWERTY, AZERTY : U+00C0 : Alt(0192) : LATIN CAPITAL LETTER A WITH GRAVE
        macro_cap_a_grave: macro_cap_a_grave {
            compatible = "zmk,behavior-macro";
            #binding-cells = <0>;
            bindings
                = <&macro_press &kp L_CTL &kp L_SHIFT>
                , <&macro_tap &kp U &kp N0 &kp N0 &kp C &kp N0 &kp SPACE>
                , <&macro_release &kp L_CTL &kp L_SHIFT>
                ;
        };
        macro_cap_a_grave_win: macro_cap_a_grave_win {
            compatible = "zmk,behavior-macro";
            #binding-cells = <0>;
            bindings
                = <&macro_press &kp L_ALT>
                , <&macro_tap &kp N0 &kp N1 &kp N9 &kp N2>
                , <&macro_release &kp L_ALT>
                ;
        };
        ////// Symboles //////
        // { : QWERTY : LBRC
        // { : AZERTY : RA(N4)
        ////// Symboles Shift //////
        // ˇ (MODIFIER) : QWERTY, AZERTY : TODO ACCENT CIRCONFLEXE INVERSÉ LAYER TOG


        ////// Normal et Shift //////
        // S : QWERTY, AZERTY : S
        ////// 1DK //////
        // é : QWERTY : U+00E9 : Alt(0233) : LATIN SMALL LETTER E WITH ACUTE
        macro_e_acute_qwerty: macro_e_acute_qwerty {
            compatible = "zmk,behavior-macro";
            #binding-cells = <0>;
            bindings
                = <&macro_press &kp L_CTL &kp L_SHIFT>
                , <&macro_tap &kp U &kp N0 &kp N0 &kp E &kp N9 &kp SPACE>
                , <&macro_release &kp L_CTL &kp L_SHIFT>
                ;
        };
        macro_e_acute_qwerty_win: macro_e_acute_qwerty_win {
            compatible = "zmk,behavior-macro";
            #binding-cells = <0>;
            bindings
                = <&macro_press &kp L_ALT>
                , <&macro_tap &kp N0 &kp N2 &kp N3 &kp N3>
                , <&macro_release &kp L_ALT>
                ;
        };  
        // é : AZERTY : N2
        ////// 1DK Shift //////
        // É : QWERTY, AZERTY : U+00C9 : Alt(0201) : LATIN CAPITAL LETTER E WITH ACUTE
        macro_cap_e_acute: macro_cap_e_acute {
            compatible = "zmk,behavior-macro";
            #binding-cells = <0>;
            bindings
                = <&macro_press &kp L_CTL &kp L_SHIFT>
                , <&macro_tap &kp U &kp N0 &kp N0 &kp C &kp N9 &kp SPACE>
                , <&macro_release &kp L_CTL &kp L_SHIFT>
                ;
        };
        macro_cap_e_acute_win: macro_cap_e_acute_win {
            compatible = "zmk,behavior-macro";
            #binding-cells = <0>;
            bindings
                = <&macro_press &kp L_ALT>
                , <&macro_tap &kp N0 &kp N2 &kp N0 &kp N1>
                , <&macro_release &kp L_ALT>
                ;
        };
        ////// Symboles //////
        // ( : QWERTY : LPAR
        // ( : AZERTY : N5
        ////// Symboles Shift //////
        // NONE


        ////// Normal et Shift //////
        // E : QWERTY, AZERTY : E
        ////// 1DK //////
        // è : QWERTY : U+00E8 : Alt(0232) : LATIN SMALL LETTER E WITH GRAVE
        macro_e_grave_qwerty: macro_e_grave_qwerty {
            compatible = "zmk,behavior-macro";
            #binding-cells = <0>;
            bindings
                = <&macro_press &kp L_CTL &kp L_SHIFT>
                , <&macro_tap &kp U &kp N0 &kp N0 &kp E &kp N8 &kp SPACE>
                , <&macro_release &kp L_CTL &kp L_SHIFT>
                ;
        };
        macro_e_grave_qwerty_win: macro_e_grave_qwerty_win {
            compatible = "zmk,behavior-macro";
            #binding-cells = <0>;
            bindings
                = <&macro_press &kp L_ALT>
                , <&macro_tap &kp N0 &kp N2 &kp N3 &kp N2>
                , <&macro_release &kp L_ALT>
                ;
        };
        // è : AZERTY : N3
        ////// 1DK Shift //////
        // È : QWERTY, AZERTY : U+00C8 : Alt(0200) : LATIN CAPITAL LETTER E WITH GRAVE
        macro_cap_e_grave: macro_cap_e_grave {
            compatible = "zmk,behavior-macro";
            #binding-cells = <0>;
            bindings
                = <&macro_press &kp L_CTL &kp L_SHIFT>
                , <&macro_tap &kp U &kp N0 &kp N0 &kp C &kp N8 &kp SPACE>
                , <&macro_release &kp L_CTL &kp L_SHIFT>
                ;
        };
        macro_cap_e_grave_win: macro_cap_e_grave_win {
            compatible = "zmk,behavior-macro";
            #binding-cells = <0>;
            bindings
                = <&macro_press &kp L_ALT>
                , <&macro_tap &kp N0 &kp N2 &kp N0 &kp N0>
                , <&macro_release &kp L_ALT>
                ;
        };
        ////// Symboles //////
        // ) : QWERTY : RPAR
        // ) : AZERTY : MINUS
        ////// Symboles Shift //////
        // NONE


        ////// Normal et Shift //////
        // N : QWERTY, AZERTY : N
        ////// 1DK //////
        // ê : QWERTY, AZERTY : U+00EA : Alt(234) : LATIN SMALL LETTER E WITH CIRCUMFLEX
        macro_e_circ: macro_e_circonflexe {
            compatible = "zmk,behavior-macro";
            #binding-cells = <0>;
            bindings
                = <&macro_press &kp L_CTL &kp L_SHIFT>
                , <&macro_tap &kp U &kp N0 &kp N0 &kp E &kp A &kp SPACE>
                , <&macro_release &kp L_CTL &kp L_SHIFT>
                ;
        };
        macro_e_circ_win: macro_e_circonflexe_win {
            compatible = "zmk,behavior-macro";
            #binding-cells = <0>;
            bindings
                = <&macro_press &kp L_ALT>
                , <&macro_tap &kp N0 &kp N2 &kp N3 &kp N4>
                , <&macro_release &kp L_ALT>
                ;
        };
        ////// 1DK Shift //////
        // Ê : QWERTY, AZERTY : U+00CA : Alt(0202) : LATIN CAPITAL LETTER E WITH CIRCUMFLEX
        macro_cap_e_circ: macro_cap_e_circonflexe {
            compatible = "zmk,behavior-macro";
            #binding-cells = <0>;
            bindings
                = <&macro_press &kp L_CTL &kp L_SHIFT>
                , <&macro_tap &kp U &kp N0 &kp N0 &kp C &kp A &kp SPACE>
                , <&macro_release &kp L_CTL &kp L_SHIFT>
                ;
        };
        macro_cap_e_circ_win: macro_cap_e_circonflexe_win {
            compatible = "zmk,behavior-macro";
            #binding-cells = <0>;
            bindings
                = <&macro_press &kp L_ALT>
                , <&macro_tap &kp N0 &kp N2 &kp N0 &kp N2>
                , <&macro_release &kp L_ALT>
                ;
        };
        ////// Symboles //////
        // } : QWERTY : RBRC
        // } : AZERTY : RA(EQUAL)
        ////// Symboles Shift //////
        // ˙ (MODIFIER) : QWERTY, AZERTY : TODO ACCENT POINT LAYER TOG


        ////// Normal et Shift //////
        // F : QWERTY, AZERTY : F
        ////// 1DK //////
        // ñ : QWERTY, AZERTY : U+00F1 : Alt(0241) : LATIN SMALL LETTER N WITH TILDE
        macro_n_tilde: macro_n_tilde {
            compatible = "zmk,behavior-macro";
            #binding-cells = <0>;
            bindings
                = <&macro_press &kp L_CTL &kp L_SHIFT>
                , <&macro_tap &kp U &kp N0 &kp N0 &kp F &kp N1 &kp SPACE>
                , <&macro_release &kp L_CTL &kp L_SHIFT>
                ;
        };
        macro_n_tilde_win: macro_n_tilde_win {
            compatible = "zmk,behavior-macro";
            #binding-cells = <0>;
            bindings
                = <&macro_press &kp L_ALT>
                , <&macro_tap &kp N0 &kp N2 &kp N4 &kp N1>
                , <&macro_release &kp L_ALT>
                ;
        };
        ////// 1DK Shift //////
        // Ñ : QWERTY, AZERTY : U+00D1 : Alt(0209) : LATIN CAPITAL LETTER N WITH TILDE
        macro_cap_n_tilde: macro_cap_n_tilde {
            compatible = "zmk,behavior-macro";
            #binding-cells = <0>;
            bindings
                = <&macro_press &kp L_CTL &kp L_SHIFT>
                , <&macro_tap &kp U &kp N0 &kp N0 &kp D &kp N1 &kp SPACE>
                , <&macro_release &kp L_CTL &kp L_SHIFT>
                ;
        };
        macro_cap_n_tilde_win: macro_cap_n_tilde_win {
            compatible = "zmk,behavior-macro";
            #binding-cells = <0>;
            bindings
                = <&macro_press &kp L_ALT>
                , <&macro_tap &kp N0 &kp N2 &kp N0 &kp N9>
                , <&macro_release &kp L_ALT>
                ;
        };
        ////// Symboles //////
        // = : QWERTY, AZERTY : EQUAL
        ////// Symboles Shift //////
        // ≠ : QWERTY, AZERTY : U+2260 : NOT EQUAL TO
        // ≠ : NO macro_not_equal_win
        macro_not_equal: macro_not_equal {
            compatible = "zmk,behavior-macro";
            #binding-cells = <0>;
            bindings
                = <&macro_press &kp L_CTL &kp L_SHIFT>
                , <&macro_tap &kp U &kp N2 &kp N2 &kp N6 &kp N0 &kp SPACE>
                , <&macro_release &kp L_CTL &kp L_SHIFT>
                ;
        };


        ////// Normal et Shift //////
        // L : QWERTY, AZERTY : L
        ////// 1DK //////
        // ( : QWERTY : LPAR
        // ( : AZERTY : N5
        ////// 1DK Shift //////
        // NONE
        ////// Symboles //////
        // \ : QWERTY : BSLH
        // \ : AZERTY : RA(N8)
        ////// Symboles Shift //////
        // / (MODIFIER) : QWERTY, AZERTY : TODO CROSSED OUT LAYER TOG


        ////// Normal et Shift //////
        // R : QWERTY, AZERTY : R
        ////// 1DK //////
        // ) : QWERTY : RPAR
        // ) : AZERTY : MINUS
        ////// 1DK Shift //////
        // NONE
        ////// Symboles //////
        // + : QWERTY, AZERTY : PLUS
        ////// Symboles Shift //////
        // ± : QWERTY, AZERTY : U+00B1 : Alt(0177) : PLUS-MINUS SIGN {biquintile (astrological aspect: 144°)}
        macro_plus_minus: macro_plus_minus {
            compatible = "zmk,behavior-macro";
            #binding-cells = <0>;
            bindings
                = <&macro_press &kp L_CTL &kp L_SHIFT>
                , <&macro_tap &kp U &kp N0 &kp N0 &kp B &kp N1 &kp SPACE>
                , <&macro_release &kp L_CTL &kp L_SHIFT>
                ;
        };
        // ± : Alt(0177) : PLUS-MINUS SIGN {biquintile (astrological aspect: 144°)}
        macro_plus_minus_win: macro_plus_minus_win {
            compatible = "zmk,behavior-macro";
            #binding-cells = <0>;
            bindings
                = <&macro_press &kp L_ALT>
                , <&macro_tap &kp N0 &kp N1 &kp N7 &kp N7>
                , <&macro_release &kp L_ALT>
                ;
        };


        ////// Normal et Shift //////
        // T : QWERTY, AZERTY : T
        ////// 1DK //////
        // î : U+00EE : Alt(0238) : LATIN SMALL LETTER I WITH CIRCUMFLEX
        macro_i_circ: macro_i_circ {
            compatible = "zmk,behavior-macro";
            #binding-cells = <0>;
            bindings
                = <&macro_press &kp L_CTL &kp L_SHIFT>
                , <&macro_tap &kp U &kp N0 &kp N0 &kp E &kp E &kp SPACE>
                , <&macro_release &kp L_CTL &kp L_SHIFT>
                ;
        };
        macro_i_circ_win: macro_i_circ_win {
            compatible = "zmk,behavior-macro";
            #binding-cells = <0>;
            bindings
                = <&macro_press &kp L_ALT>
                , <&macro_tap &kp N0 &kp N2 &kp N3 &kp N8>
                , <&macro_release &kp L_ALT>
                ;
        };
        ////// 1DK Shift //////
        // Î : U+00CE : Alt(0206) : LATIN CAPITAL LETTER I WITH CIRCUMFLEX
        macro_cap_i_circ: macro_cap_i_circ {
            compatible = "zmk,behavior-macro";
            #binding-cells = <0>;
            bindings
                = <&macro_press &kp L_CTL &kp L_SHIFT>
                , <&macro_tap &kp U &kp N0 &kp N0 &kp C &kp E &kp SPACE>
                , <&macro_release &kp L_CTL &kp L_SHIFT>
                ;
        };
        macro_cap_i_circ_win: macro_cap_i_circ_win {
            compatible = "zmk,behavior-macro";
            #binding-cells = <0>;
            bindings
                = <&macro_press &kp L_ALT>
                , <&macro_tap &kp N0 &kp N2 &kp N0 &kp N6>
                , <&macro_release &kp L_ALT>
                ;
        };
        ////// Symboles //////
        // - : QWERTY : MINUS
        // - : AZERTY : N6
        ////// Symboles Shift //////
        // ¯ (MODIFIER) : QWERTY, AZERTY : TODO FLAT ACCENT LAYER TOG


        ////// Normal et Shift //////
        // I : QWERTY, AZERTY : I
        ////// 1DK //////
        // ï : QWERTY, AZERTY : U+00EF : Alt(0239) : LATIN SMALL LETTER I WITH DIAERESIS
        macro_i_trema: macro_i_trema {
            compatible = "zmk,behavior-macro";
            #binding-cells = <0>;
            bindings
                = <&macro_press &kp L_CTL &kp L_SHIFT>
                , <&macro_tap &kp U &kp N0 &kp N0 &kp E &kp F &kp SPACE>
                , <&macro_release &kp L_CTL &kp L_SHIFT>
                ;
        };
        macro_i_trema_win: macro_i_trema_win {
            compatible = "zmk,behavior-macro";
            #binding-cells = <0>;
            bindings
                = <&macro_press &kp L_ALT>
                , <&macro_tap &kp N0 &kp N2 &kp N3 &kp N9>
                , <&macro_release &kp L_ALT>
                ;
        };
        ////// 1DK Shift //////
        // Ï : QWERTY, AZERTY : U+00CF : Alt(0207) : LATIN CAPITAL LETTER I WITH DIAERESIS
        macro_cap_i_trema: macro_cap_i_trema {
            compatible = "zmk,behavior-macro";
            #binding-cells = <0>;
            bindings
                = <&macro_press &kp L_CTL &kp L_SHIFT>
                , <&macro_tap &kp U &kp N0 &kp N0 &kp C &kp F &kp SPACE>
                , <&macro_release &kp L_CTL &kp L_SHIFT>
                ;
        };
        macro_cap_i_trema_win: macro_cap_i_trema_win {
            compatible = "zmk,behavior-macro";
            #binding-cells = <0>;
            bindings
                = <&macro_press &kp L_ALT>
                , <&macro_tap &kp N0 &kp N2 &kp N0 &kp N7>
                , <&macro_release &kp L_ALT>
                ;
        };
        ////// Symboles //////
        // / : QWERTY : FSLH
        // / : AZERTY : LS(DOT)
        ////// Symboles Shift //////
        // ÷ : QWERTY, AZERTY : U+00F7 : Alt(0247) : DIVISION SIGN {obelus}
        macro_division: macro_division {
            compatible = "zmk,behavior-macro";
            #binding-cells = <0>;
            bindings
                = <&macro_press &kp L_CTL &kp L_SHIFT>
                , <&macro_tap &kp U &kp N0 &kp N0 &kp F &kp N7 &kp SPACE>
                , <&macro_release &kp L_CTL &kp L_SHIFT>
                ;
        };
        macro_division_win: macro_division_win {
            compatible = "zmk,behavior-macro";
            #binding-cells = <0>;
            bindings
                = <&macro_press &kp L_ALT>
                , <&macro_tap &kp N0 &kp N2 &kp N4 &kp N7>
                , <&macro_release &kp L_ALT>
                ;
        };


        ////// Normal et Shift //////
        // U : QWERTY, AZERTY : U
        ////// 1DK //////
        // ù : AZERTY : SQT
        // ù : QWERTY : U+00F9 : Alt(0249) : LATIN SMALL LETTER U WITH GRAVE
        macro_u_grave_qwerty: macro_u_grave_qwerty {
            compatible = "zmk,behavior-macro";
            #binding-cells = <0>;
            bindings
                = <&macro_press &kp L_CTL &kp L_SHIFT>
                , <&macro_tap &kp U &kp N0 &kp N0 &kp F &kp N9 &kp SPACE>
                , <&macro_release &kp L_CTL &kp L_SHIFT>
                ;
        };
        macro_u_grave_qwerty_win: macro_u_grave_qwerty_win {
            compatible = "zmk,behavior-macro";
            #binding-cells = <0>;
            bindings
                = <&macro_press &kp L_ALT>
                , <&macro_tap &kp N0 &kp N2 &kp N4 &kp N9>
                , <&macro_release &kp L_ALT>
                ;
        };
        ////// 1DK Shift //////
        // Ù : QWERTY, AZERTY : U+00D9 : Alt(0217) : LATIN CAPITAL LETTER U WITH GRAVE
        macro_cap_u_grave: macro_cap_u_grave {
            compatible = "zmk,behavior-macro";
            #binding-cells = <0>;
            bindings
                = <&macro_press &kp L_CTL &kp L_SHIFT>
                , <&macro_tap &kp U &kp N0 &kp N0 &kp D &kp N9 &kp SPACE>
                , <&macro_release &kp L_CTL &kp L_SHIFT>
                ;
        };
        macro_cap_u_grave_win: macro_cap_u_grave_win {
            compatible = "zmk,behavior-macro";
            #binding-cells = <0>;
            bindings
                = <&macro_press &kp L_ALT>
                , <&macro_tap &kp N0 &kp N2 &kp N1 &kp N7>
                , <&macro_release &kp L_ALT>
                ;
        };
        ////// Symboles //////
        // " : QWERTY : DQT
        // " : AZERTY : N3
        ////// Symboles Shift //////
        // ˝ (MODIFIER) : QWERTY, AZERTY : TODO ACCENT DOUBLE AIGU LAYER TOG


        // ENTER
        // TRANS
        // TRANS
        // TRANS
        // TRANS


        /////////////////////////////////////////////////////////////////////////////
        // Rangée 4                                                                //
        /////////////////////////////////////////////////////////////////////////////

        // L_SHIFT
        // TRANS
        // TRANS
        // TRANS
        // TRANS


        ////// Normal et Shift //////
        // Z : QWERTY : Z
        // Z : AZERTY : W
        ////// 1DK //////
        // æ : QWERTY, AZERTY : U+00E6 : Alt(0230) : LATIN SMALL LETTER AE {latin small ligature ae (1.1); ash (from Old English æsc)}
        macro_a_e: macro_a_e {
            compatible = "zmk,behavior-macro";
            #binding-cells = <0>;
            bindings
                = <&macro_press &kp L_CTL &kp L_SHIFT>
                , <&macro_tap &kp U &kp N0 &kp N0 &kp E &kp N6 &kp SPACE>
                , <&macro_release &kp L_CTL &kp L_SHIFT>
                ;
        };
        macro_a_e_win: macro_a_e_win {
            compatible = "zmk,behavior-macro";
            #binding-cells = <0>;
            bindings
                = <&macro_press &kp L_ALT>
                , <&macro_tap &kp N0 &kp N2 &kp N3 &kp N0>
                , <&macro_release &kp L_ALT>
                ;
        };
        ////// 1DK Shift //////
        // Æ : QWERTY, AZERTY : U+00C6 : Alt(0198) : LATIN CAPITAL LETTER AE {latin capital ligature ae (1.1)}
        macro_cap_a_e: macro_cap_a_e {
            compatible = "zmk,behavior-macro";
            #binding-cells = <0>;
            bindings
                = <&macro_press &kp L_CTL &kp L_SHIFT>
                , <&macro_tap &kp U &kp N0 &kp N0 &kp C &kp N6 &kp SPACE>
                , <&macro_release &kp L_CTL &kp L_SHIFT>
                ;
        };
        macro_cap_a_e_win: macro_cap_a_e_win {
            compatible = "zmk,behavior-macro";
            #binding-cells = <0>;
            bindings
                = <&macro_press &kp L_ALT>
                , <&macro_tap &kp N0 &kp N1 &kp N9 &kp N8>
                , <&macro_release &kp L_ALT>
                ;
        };
        ////// Symboles //////
        // ~ : QUERTY : TILDE
        // ~ : AZERTY : RA(N2)
        ////// Symboles Shift //////
        // ~ : TODO ACCENT TILDE LAYER TOG


        ////// Normal et Shift //////
        // X : QWERTY, AZERTY : X
        ////// 1DK //////
        // ß : QWERTY, AZERTY : U+00DF : Alt(0223) : LATIN SMALL LETTER SHARP S {Eszett}
        macro_s_eszett: macro_s_eszett {
            compatible = "zmk,behavior-macro";
            #binding-cells = <0>;
            bindings
                = <&macro_press &kp L_CTL &kp L_SHIFT>
                , <&macro_tap &kp U &kp N0 &kp N0 &kp D &kp F &kp SPACE>
                , <&macro_release &kp L_CTL &kp L_SHIFT>
                ;
        };
        macro_s_eszett_win: macro_s_eszett_win {
            compatible = "zmk,behavior-macro";
            #binding-cells = <0>;
            bindings
                = <&macro_press &kp L_ALT>
                , <&macro_tap &kp N0 &kp N2 &kp N2 &kp N3>
                , <&macro_release &kp L_ALT>
                ;
        };
        ////// 1DK Shift //////
        // ẞ : QWERTY, AZERTY : U+1E9E : LATIN CAPITAL LETTER SHARP S
        macro_s_sharp: macro_s_sharp {
            compatible = "zmk,behavior-macro";
            #binding-cells = <0>;
            bindings
                = <&macro_press &kp L_CTL &kp L_SHIFT>
                , <&macro_tap &kp U &kp N1 &kp E &kp N9 &kp E &kp SPACE>
                , <&macro_release &kp L_CTL &kp L_SHIFT>
                ;
        };
        // ẞ : NO macro_s_sharp_win : NONE
        ////// Symboles //////
        // [ : QWERTY : LBKT
        // [ : AZERTY : RA(N5)
        ////// Symboles Shift //////
        // , (MODIFIER) : QWERTY, AZERTY : TODO CÉDILLE LAYER TOG


        ////// Normal //////
        // - : QWERTY : MINUS
        // - : AZERTY : N6
        ////// Shift //////
        // ? : QWERTY : QMARK
        // ? : AZERTY : LS(M)
        ////// 1DK //////
        // ‑ : QWERTY, AZERTY : U+2011 : NON-BREAKING HYPHEN
        macro_nb_hyphen: macro_non_breaking_hyphen {
            compatible = "zmk,behavior-macro";
            #binding-cells = <0>;
            bindings
                = <&macro_press &kp L_CTL &kp L_SHIFT>
                , <&macro_tap &kp U &kp N2 &kp N0 &kp N1 &kp N1 &kp SPACE>
                , <&macro_release &kp L_CTL &kp L_SHIFT>
                ;
        };
        // ‑ : NO macro_nb_hyphen_win : NONE
        ////// 1DK Shift //////
        // ¿ : QWERTY, AZERTY : U+00BF : Alt(0191) : INVERTED QUESTION MARK {turned question mark}
        macro_inv_qmark: macro_inv_question_mark {
            compatible = "zmk,behavior-macro";
            #binding-cells = <0>;
            bindings
                = <&macro_press &kp L_CTL &kp L_SHIFT>
                , <&macro_tap &kp U &kp N0 &kp N0 &kp B &kp F &kp SPACE>
                , <&macro_release &kp L_CTL &kp L_SHIFT>
                ;
        };
        macro_inv_qmark_win: macro_inv_question_mark_win {
            compatible = "zmk,behavior-macro";
            #binding-cells = <0>;
            bindings
                = <&macro_press &kp L_ALT>
                , <&macro_tap &kp N0 &kp N1 &kp N9 &kp N1>
                , <&macro_release &kp L_ALT>
                ;
        };
        ////// Symboles //////
        // ] : QWERTY : RBKT
        // ] : AZERTY : RA(MINUS)
        ////// Symboles Shift //////
        // ˛ (MODIFIER) : QWERTY, AZERTY : TODO CÉDILLE INVERSÉE LAYER TOG


        ////// Normal et Shift //////
        // V : QWERTY, AZERTY : V
        ////// 1DK //////
        // – : QWERTY, AZERTY : U+2013 : Alt(0150) : EN DASH
        macro_en_dash: macro_en_dash {
            compatible = "zmk,behavior-macro";
            #binding-cells = <0>;
            bindings
                = <&macro_press &kp L_CTL &kp L_SHIFT>
                , <&macro_tap &kp U &kp N2 &kp N0 &kp N1 &kp N3 &kp SPACE>
                , <&macro_release &kp L_CTL &kp L_SHIFT>
                ;
        };
        macro_en_dash_win: macro_en_dash_win {
            compatible = "zmk,behavior-macro";
            #binding-cells = <0>;
            bindings
                = <&macro_press &kp L_ALT>
                , <&macro_tap &kp N0 &kp N1 &kp N5 &kp N0>
                , <&macro_release &kp L_ALT>
                ;
        };
        ////// 1DK Shift //////
        // NONE
        ////// Symboles //////
        // _ : QWERTY : UNDER
        // _ : AZERTY : RA(N8)
        ////// Symboles Shift //////
        // – : QWERTY, AZERTY : U+2013 : Alt(0150) : EN DASH
        // macro_en_dash
        // macro_en_dash_win


        ////// Normal et Shift //////
        // B : QWERTY, AZERTY : B
        ////// 1DK //////
        // — : QWERTY, AZERTY : U+2014 : Alt(0151) : EM DASH
        macro_em_dash: macro_em_dash {
            compatible = "zmk,behavior-macro";
            #binding-cells = <0>;
            bindings
                = <&macro_press &kp L_CTL &kp L_SHIFT>
                , <&macro_tap &kp U &kp N2 &kp N0 &kp N1 &kp N4 &kp SPACE>
                , <&macro_release &kp L_CTL &kp L_SHIFT>
                ;
        };
        macro_em_dash_win: macro_em_dash_win {
            compatible = "zmk,behavior-macro";
            #binding-cells = <0>;
            bindings
                = <&macro_press &kp L_ALT>
                , <&macro_tap &kp N0 &kp N1 &kp N5 &kp N1>
                , <&macro_release &kp L_ALT>
                ;
        };
        ////// 1DK Shift //////
        // NONE
        ////// Symboles //////
        // # : QWERTY : HASH
        // # : AZERTY : RA(N3)
        ////// Symboles Shift //////
        // NONE


        ////// Normal //////
        // . : QWERTY : DOT
        // . : AZERTY : LS(COMMA)
        ////// Shift //////
        // : : QWERTY : COLON
        // : : AZERTY : DOT
        ////// 1DK ////////
        // … : QWERTY, AZERTY : U+2026 : Alt(0133) : HORIZONTAL ELLIPSIS {three dot leader}
        macro_h_ellipsis: macro_horizontal_ellipsis {
            compatible = "zmk,behavior-macro";
            #binding-cells = <0>;
            bindings
                = <&macro_press &kp L_CTL &kp L_SHIFT>
                , <&macro_tap &kp U &kp N2 &kp N0 &kp N2 &kp N6 &kp SPACE>
                , <&macro_release &kp L_CTL &kp L_SHIFT>
                ;
        };
        macro_h_ellipsis_win: macro_horizontal_ellipsis_win {
            compatible = "zmk,behavior-macro";
            #binding-cells = <0>;
            bindings
                = <&macro_press &kp L_ALT>
                , <&macro_tap &kp N0 &kp N1 &kp N3 &kp N3>
                , <&macro_release &kp L_ALT>
                ;
        };
        ////// Symboles //////
        // | : QWERTY : PIPE
        // | : AZERTY : RA(N6)
        ////// Symboles Shift //////
        // ¦ : QWERTY, AZERTY : U+00A6 : Alt(0166) : BROKEN BAR {parted rule (in typography)}
        macro_broken_bar: macro_broken_bar {
            compatible = "zmk,behavior-macro";
            #binding-cells = <0>;
            bindings
                = <&macro_press &kp L_CTL &kp L_SHIFT>
                , <&macro_tap &kp U &kp N0 &kp N0 &kp A &kp N6 &kp SPACE>
                , <&macro_release &kp L_CTL &kp L_SHIFT>
                ;
        };
        macro_broken_bar_win: macro_broken_bar_win {
            compatible = "zmk,behavior-macro";
            #binding-cells = <0>;
            bindings
                = <&macro_press &kp L_ALT>
                , <&macro_tap &kp N0 &kp N1 &kp N6 &kp N6>
                , <&macro_release &kp L_ALT>
                ;
        };


        ////// Normal et Shift //////
        // H : QWERTY, AZERTY : H
        ////// 1DK //////
        // NONE
        ////// 1DK Shift //////
        // NONE
        ////// Symboles //////
        // ! : QWERTY : EXCL
        // ! : AZERTY : FSLH
        ////// Symboles Shift //////
        // ¬ : QWERTY, AZERTY : U+00AC : Alt(0172) : NOT SIGN {angled dash (in typography)}
        macro_not: macro_not {
            compatible = "zmk,behavior-macro";
            #binding-cells = <0>;
            bindings
                = <&macro_press &kp L_CTL &kp L_SHIFT>
                , <&macro_tap &kp U &kp N0 &kp N0 &kp A &kp C &kp SPACE>
                , <&macro_release &kp L_CTL &kp L_SHIFT>
                ;
        };
        macro_not_win: macro_not_win {
            compatible = "zmk,behavior-macro";
            #binding-cells = <0>;
            bindings
                = <&macro_press &kp L_ALT>
                , <&macro_tap &kp N0 &kp N1 &kp N7 &kp N2>
                , <&macro_release &kp L_ALT>
                ;
        };


        ////// Normal et Shift //////
        // G : QWERTY, AZERTY : G
        ////// 1DK ////////
        // TODO ALPHABET GREC LAYER TOG 
        ////// 1DK Shift ////////
        // NONE
        ////// Symboles //////
        // ; : QWERTY : SEMI
        // ; : AZERTY : COMMA
        ////// Symboles Shift //////
        // ¸ (MODIFIER) : QWERTY, AZERTY : TODO CÉDILLE COURBE LAYER TOG

;
        ////// Normal //////
        // , : QWERTY : COMMA
        // , : AZERTY : M
        ////// Shift //////
        // ; : QWERTY : SEMI
        // ; : AZERTY : COMMA
        ////// 1DK ////////
        // · : QWERTY, AZERTY : U+00B7 : Alt(0183) : MIDDLE DOT {midpoint (in typography); Georgian comma; Greek middle dot (ano teleia)}
        macro_mid_dot: macro_middle_dot {
            compatible = "zmk,behavior-macro";
            #binding-cells = <0>;
            bindings
                = <&macro_press &kp L_CTL &kp L_SHIFT>
                , <&macro_tap &kp U &kp N0 &kp N0 &kp B &kp N7 &kp SPACE>
                , <&macro_release &kp L_CTL &kp L_SHIFT>
                ;
        };
        macro_mid_dot_win: macro_middle_dot_win {
            compatible = "zmk,behavior-macro";
            #binding-cells = <0>;
            bindings
                = <&macro_press &kp L_ALT>
                , <&macro_tap &kp N0 &kp N1 &kp N8 &kp N3>
                , <&macro_release &kp L_ALT>
                ;
        };
        ////// 1DK Shift ////////
        // • : QWERTY, AZERTY : U+2022 : Alt(0149) : BULLET {black small circle}
        macro_bullet: macro_bullet {
            compatible = "zmk,behavior-macro";
            #binding-cells = <0>;
            bindings
                = <&macro_press &kp L_CTL &kp L_SHIFT>
                , <&macro_tap &kp U &kp N2 &kp N0 &kp N2 &kp N2 &kp SPACE>
                , <&macro_release &kp L_CTL &kp L_SHIFT>
                ;
        };
        macro_bullet_win: macro_bullet_win {
            compatible = "zmk,behavior-macro";
            #binding-cells = <0>;
            bindings
                = <&macro_press &kp L_ALT>
                , <&macro_tap &kp N0 &kp N1 &kp N4 &kp N9>
                , <&macro_release &kp L_ALT>
                ;
        };
        ////// Symboles //////
        // : : QWERTY : COLON
        // : : AZERTY : DOT
        ////// Symboles Shift //////
        // : : QWERTY : COLON
        // : : AZERTY : DOT
        

        ////// Normal et Shift //////
        // K : QWERTY, AZERTY : K
        ////// 1DK ////////
        // NONE
        ////// 1DK Shift ////////
        // NONE
        ////// Symboles //////
        // ? : QWERTY : QMARK
        // ? : AZERTY : LS(M)
        ////// Symboles Shift //////
        // ˘ : QWERTY, AZERTY : TODO ACCENT CIRCONFLEXE INVERSÉ ARRONDI LAYER TOG


        // R_SHIFT
        // TRANS
        // TRANS
        // TRANS
        // TRANS


        /////////////////////////////////////////////////////////////////////////////
        // Rangée 5                                                                //
        /////////////////////////////////////////////////////////////////////////////

        // L_GUI
        // TRANS
        // TRANS
        // TRANS
        // TRANS
        
        // L_ALT
        // TRANS
        // TRANS
        // TRANS
        // TRANS

        // LAYER MOD NAV

        ////// Normal //////
        // QWERTY, AZERTY : SPACE
        ////// Shift //////
        // espace insécable fine : QWERTY, AZERTY : U+202F : NARROW NO-BREAK SPACE [NNBSP]
        macro_sp_insec_fine: macro_space_insec {
            compatible = "zmk,behavior-macro";
            #binding-cells = <0>;
            bindings
                = <&macro_press &kp L_CTL &kp L_SHIFT>
                , <&macro_tap &kp U &kp N2 &kp N0 &kp N2 &kp F &kp SPACE>
                , <&macro_release &kp L_CTL &kp L_SHIFT>
                ;
        };
        // espace insécable fine : NO macro_sp_insec_fine_win 
        ////// 1DK ////////
        // ’ : QWERTY, AZERTY : macro_sqm_r : voir touche N3
        ////// 1DK Shift ////////
        // ’ : QWERTY, AZERTY : macro_sqm_r : voir touche N3
        ////// Symboles //////
        // SPACE : QWERTY, AZERTY : SPACE
        ////// Symboles Shift //////
        // espace insécable : QWERTY, AZERTY : U+00A0 : Alt(0160) : NO-BREAK SPACE [NBSP]
        macro_sp_insec: macro_sp_insec {
            compatible = "zmk,behavior-macro";
            #binding-cells = <0>;
            bindings
                = <&macro_press &kp L_CTL &kp L_SHIFT>
                , <&macro_tap &kp U &kp N0 &kp N0 &kp A &kp N0 &kp SPACE>
                , <&macro_release &kp L_CTL &kp L_SHIFT>
                ;
        };
        macro_sp_insec_win: macro_sp_insec_win {
            compatible = "zmk,behavior-macro";
            #binding-cells = <0>;
            bindings
                = <&macro_press &kp L_ALT>
                , <&macro_tap &kp N0 &kp N1 &kp N6 &kp N0>
                , <&macro_release &kp L_ALT>
                ;
        };
        
        // L_CTL
        // TRANS
        // TRANS
        // TRANS
        // TRANS


        // R_CTL
        // TRANS
        // TRANS
        // TRANS
        // TRANS


        ////// Normal //////
        // QWERTY, AZERTY : SPACE
        ////// Shift //////
        // espace insécable fine : QWERTY, AZERTY : macro_sp_insec_fine : voir touche SPACE gauche
        // espace insécable fine : NO macro_sp_insec_fine_win 
        ////// 1DK ////////
        // ’ : QWERTY, AZERTY : macro_sqm_r : voir touche N3
        ////// 1DK Shift ////////
        // ’ : QWERTY, AZERTY : macro_sqm_r : voir touche N3
        ////// Symboles //////
        // SPACE : QWERTY, AZERTY : SPACE
        ////// Symboles Shift //////
        // espace insécable : QWERTY, AZERTY : macro_sp_insec & macro_sp_insec_win : voir touche SPACE gauche

        // LAYER MOD CHARS
    

        // R_ALT
        // TRANS
        // TRANS
        // TRANS
        // TRANS


        // R_GUI
        // TRANS
        // TRANS
        // TRANS
        // TRANS

    };    

    behaviors {
        /////////////////////////////////////////////////////////////////////////////
        // Rangée 1                                                                //
        /////////////////////////////////////////////////////////////////////////////

        // ESC et `
        gresc_qwerty: grave_escape_qwerty {
            compatible = "zmk,behavior-mod-morph";
            #binding-cells = <0>;
            bindings = <&kp ESC>, <&kp GRAVE>;
            mods = <(MOD_LGUI|MOD_LSFT|MOD_RGUI|MOD_RSFT)>;
        };
        gresc_azerty: grave_escape_azerty {
            compatible = "zmk,behavior-mod-morph";
            #binding-cells = <0>;
            bindings = <&kp ESC>, <&macro_grave_azerty>;
            mods = <(MOD_LGUI|MOD_LSFT|MOD_RGUI|MOD_RSFT)>;
        };


        // N1 et € 
        n1_euro_qwerty: n1_euro_qwerty {
            compatible = "zmk,behavior-mod-morph";
            #binding-cells = <0>;
            bindings = <&kp N1>, <&kp RA(N5)>;
            mods = <(MOD_LSFT|MOD_RSFT)>;
        };
        n1_euro_azerty: n1_euro_azerty {
            compatible = "zmk,behavior-mod-morph";
            #binding-cells = <0>;
            bindings = <&kp LS(N1)>, <&kp RA(E)>;
            mods = <(MOD_LSFT|MOD_RSFT)>;
        };


        // N2 et «
        n2_chevron_l_qwerty: n2_chevron_left_qwerty {
            compatible = "zmk,behavior-mod-morph";
            #binding-cells = <0>;
            bindings = <&kp N2>, <&macro_chevron_l>;
            mods = <(MOD_LSFT|MOD_RSFT)>;
        };
        n2_chevron_l_qwerty_win: n2_chevron_left_qwerty_win {
            compatible = "zmk,behavior-mod-morph";
            #binding-cells = <0>;
            bindings = <&kp N2>, <&macro_chevron_l_win>;
            mods = <(MOD_LSFT|MOD_RSFT)>;
        };
        n2_chevron_l_azerty: n2_chevron_left_azerty {
            compatible = "zmk,behavior-mod-morph";
            #binding-cells = <0>;
            bindings = <&kp LS(N2)>, <&macro_chevron_l>;
            mods = <(MOD_LSFT|MOD_RSFT)>;
        };
        n2_chevron_l_azerty_win: n2_chevron_left_azerty_win {
            compatible = "zmk,behavior-mod-morph";
            #binding-cells = <0>;
            bindings = <&kp LS(N2)>, <&macro_chevron_l_win>;
            mods = <(MOD_LSFT|MOD_RSFT)>;
        };
 

        // N3 et »
        n3_chevron_r_qwerty: n3_chevron_right_qwerty {
            compatible = "zmk,behavior-mod-morph";
            #binding-cells = <0>;
            bindings = <&kp N3>, <&macro_chevron_r>;
            mods = <(MOD_LSFT|MOD_RSFT)>;
        };
        n3_chevron_r_qwerty_win: n3_chevron_right_qwerty_win {
            compatible = "zmk,behavior-mod-morph";
            #binding-cells = <0>;
            bindings = <&kp N3>, <&macro_chevron_r_win>;
            mods = <(MOD_LSFT|MOD_RSFT)>;
        };
        n3_chevron_r_azerty: n3_chevron_right_azerty {
            compatible = "zmk,behavior-mod-morph";
            #binding-cells = <0>;
            bindings = <&kp LS(N3)>, <&macro_chevron_r>;
            mods = <(MOD_LSFT|MOD_RSFT)>;
        };
        n3_chevron_r_azerty_win: n3_chevron_right_azerty_win {
            compatible = "zmk,behavior-mod-morph";
            #binding-cells = <0>;
            bindings = <&kp LS(N3)>, <&macro_chevron_r_win>;
            mods = <(MOD_LSFT|MOD_RSFT)>;
        };


        // N4 AZERTY
        n4_azerty: n4_azerty {
            compatible = "zmk,behavior-mod-morph";
            #binding-cells = <0>;
            bindings = <&kp LS(N4)>, <&kp N4>;
            mods = <(MOD_LSFT|MOD_RSFT)>;
        };


        // N5 AZERTY
        n4_azerty: n4_azerty {
            compatible = "zmk,behavior-mod-morph";
            #binding-cells = <0>;
            bindings = <&kp LS(N5)>, <&kp N5>;
            mods = <(MOD_LSFT|MOD_RSFT)>;
        };


        // N6 AZERTY
        n4_azerty: n4_azerty {
            compatible = "zmk,behavior-mod-morph";
            #binding-cells = <0>;
            bindings = <&kp LS(N6)>, <&kp N6>;
            mods = <(MOD_LSFT|MOD_RSFT)>;
        };


        // N7 AZERTY
        n4_azerty: n4_azerty {
            compatible = "zmk,behavior-mod-morph";
            #binding-cells = <0>;
            bindings = <&kp LS(N7)>, <&kp N7>;
            mods = <(MOD_LSFT|MOD_RSFT)>;
        };


        // N8 AZERTY
        n4_azerty: n4_azerty {
            compatible = "zmk,behavior-mod-morph";
            #binding-cells = <0>;
            bindings = <&kp LS(N8)>, <&kp N8>;
            mods = <(MOD_LSFT|MOD_RSFT)>;
        };


        // N9 et #
        sharp_qwerty: sharp_qwerty {
            compatible = "zmk,behavior-mod-morph";
            #binding-cells = <0>;
            bindings = <&kp N9>, <&kp LS(N3)>;
            mods = <(MOD_LSFT|MOD_RSFT)>;
        };
        sharp_azerty: sharp_azerty {
            compatible = "zmk,behavior-mod-morph";
            #binding-cells = <0>;
            bindings = <&kp LS(N9)>, <&kp RA(N3)>;
            mods = <(MOD_LSFT|MOD_RSFT)>;
        };


        // N0 et @
        arob_qwerty: arobase_qwerty {
            compatible = "zmk,behavior-mod-morph";
            #binding-cells = <0>;
            bindings = <&kp N0>, <&kp LS(N2)>;
            mods = <(MOD_LSFT|MOD_RSFT)>;
        };
        arob_azerty: arobase_azerty {
            compatible = "zmk,behavior-mod-morph";
            #binding-cells = <0>;
            bindings = <&kp LS(N0)>, <&kp RA(Q)>;
            mods = <(MOD_LSFT|MOD_RSFT)>;
        };


        /////////////////////////////////////////////////////////////////////////////
        // Rangée 2                                                                //
        /////////////////////////////////////////////////////////////////////////////

        // â et Â
        a_circ: a_circ {
            compatible = "zmk,behavior-mod-morph";
            #binding-cells = <0>;
            bindings = <&macro_a_circ>, <&macro_cap_a_circ>;
            mods = <(MOD_LSFT|MOD_RSFT)>;
        };
        a_circ_win: a_circ_win {
            compatible = "zmk,behavior-mod-morph";
            #binding-cells = <0>;
            bindings = <&macro_a_circ_win>, <&macro_cap_a_circ_win>;
            mods = <(MOD_LSFT|MOD_RSFT)>;
        };


        // ç et Ç
        c_cedi_qwerty: c_cedi_qwerty {
            compatible = "zmk,behavior-mod-morph";
            #binding-cells = <0>;
            bindings = <&macro_c_cedi_qwerty>, <&macro_cap_c_cedi_qwerty>;
            mods = <(MOD_LSFT|MOD_RSFT)>;
        };
        c_cedi_qwerty_win: c_cedi_qwerty_win {
            compatible = "zmk,behavior-mod-morph";
            #binding-cells = <0>;
            bindings = <&macro_c_cedi_qwerty_win>, <&macro_cap_c_cedi_qwerty_win>;
            mods = <(MOD_LSFT|MOD_RSFT)>;
        };
        c_cedi_azerty: c_cedi_azerty {
            compatible = "zmk,behavior-mod-morph";
            #binding-cells = <0>;
            bindings = <&kp N9>, <&macro_cap_c_cedi_azerty>;
            mods = <(MOD_LSFT|MOD_RSFT)>;
        };
        c_cedi_azerty_win: c_cedi_azerty_win {
            compatible = "zmk,behavior-mod-morph";
            #binding-cells = <0>;
            bindings = <&kp N9>, <&macro_cap_c_cedi_azerty_win>;
            mods = <(MOD_LSFT|MOD_RSFT)>;
        };


        // œ et Œ
        o_e: o_e {
            compatible = "zmk,behavior-mod-morph";
            #binding-cells = <0>;
            bindings = <&macro_o_e>, <&macro_cap_o_e>;
            mods = <(MOD_LSFT|MOD_RSFT)>;
        };
        o_e_win: o_e_win {
            compatible = "zmk,behavior-mod-morph";
            #binding-cells = <0>;
            bindings = <&macro_o_e_win>, <&macro_cap_o_e_win>;
            mods = <(MOD_LSFT|MOD_RSFT)>;
        };

        // ô et Ô
        o_circ: o_circ {
            compatible = "zmk,behavior-mod-morph";
            #binding-cells = <0>;
            bindings = <&macro_o_circ>, <&macro_cap_o_circ>;
            mods = <(MOD_LSFT|MOD_RSFT)>;
        };
        o_circ_win: o_circ_win {
            compatible = "zmk,behavior-mod-morph";
            #binding-cells = <0>;
            bindings = <&macro_o_circ_win>, <&macro_cap_o_circ_win>;
            mods = <(MOD_LSFT|MOD_RSFT)>;
        };

        // W : no 1DK : NONE

        // J : no 1DK : NONE

        // µ et none
        micro: micro {
            compatible = "zmk,behavior-mod-morph";
            #binding-cells = <0>;
            bindings = <&macro_micro>, <&NONE>;
            mods = <(MOD_LSFT|MOD_RSFT)>;
        };
        micro_win: micro_win {
            compatible = "zmk,behavior-mod-morph";
            #binding-cells = <0>;
            bindings = <&macro_micro_win>, <&NONE>;
            mods = <(MOD_LSFT|MOD_RSFT)>;
        };


        // _ et _ 
        under_qwerty: under_qwerty {
            compatible = "zmk,behavior-mod-morph";
            #binding-cells = <0>;
            bindings = <&UNDER>, <&UNDER>;
            mods = <(MOD_LSFT|MOD_RSFT)>;
        };
        under_azerty: under_azerty {
            compatible = "zmk,behavior-mod-morph";
            #binding-cells = <0>;
            bindings = <&kp N8>, <&kp N8>;
            mods = <(MOD_LSFT|MOD_RSFT)>;
        };


        // 1DK et !
        dead1_qwerty: dead_1_key_expl_qwerty {
            compatible = "zmk,behavior-mod-morph";
            #binding-cells = <0>;
            bindings = <&sl 2>, <&kp EXCL>;
            mods = <(MOD_LSFT|MOD_RSFT)>;
        };
        dead1_azerty: dead_1_key_expl_azerty {
            compatible = "zmk,behavior-mod-morph";
            #binding-cells = <0>;
            bindings = <&sl 2>, <&kp N8>;
            mods = <(MOD_LSFT|MOD_RSFT)>;
        };


        // û et Û
        u_circ: u_circ {
            compatible = "zmk,behavior-mod-morph";
            #binding-cells = <0>;
            bindings = <&macro_u_circ>, <&macro_cap_u_circ>;
            mods = <(MOD_LSFT|MOD_RSFT)>;
        };
        u_circ_win: u_circ_win {
            compatible = "zmk,behavior-mod-morph";
            #binding-cells = <0>;
            bindings = <&macro_u_circ_win>, <&macro_cap_u_circ_win>;
            mods = <(MOD_LSFT|MOD_RSFT)>;
        };


        /////////////////////////////////////////////////////////////////////////////
        // Rangée 3                                                                //
        /////////////////////////////////////////////////////////////////////////////

        // à et À
        a_grave_qwerty: a_grave_qwerty {
            compatible = "zmk,behavior-mod-morph";
            #binding-cells = <0>;
            bindings = <&macro_a_grave_qwerty>, <&macro_cap_a_grave_qwerty>;
            mods = <(MOD_LSFT|MOD_RSFT)>;
        };
        a_grave_qwerty_win: a_grave_qwerty_win {
            compatible = "zmk,behavior-mod-morph";
            #binding-cells = <0>;
            bindings = <&macro_a_grave_qwerty_win>, <&macro_cap_a_grave_win>;
            mods = <(MOD_LSFT|MOD_RSFT)>;
        };
        a_grave_azerty: a_grave_azerty {
            compatible = "zmk,behavior-mod-morph";
            #binding-cells = <0>;
            bindings = <&kp N0>, <&macro_cap_a_grave>;
            mods = <(MOD_LSFT|MOD_RSFT)>;
        };
        a_grave_azerty_win: a_grave_azerty_win {
            compatible = "zmk,behavior-mod-morph";
            #binding-cells = <0>;
            bindings = <&kp N0>, <&macro_cap_a_grave_win>;
            mods = <(MOD_LSFT|MOD_RSFT)>;
        };


        // é et É
        e_acute_qwerty: e_acute_qwerty {
            compatible = "zmk,behavior-mod-morph";
            #binding-cells = <0>;
            bindings = <&macro_e_acute_qwerty>, <&macro_cap_e_acute>;
            mods = <(MOD_LSFT|MOD_RSFT)>;
        };
        e_acute_qwerty_win: e_acute_qwerty_win {
            compatible = "zmk,behavior-mod-morph";
            #binding-cells = <0>;
            bindings = <&macro_e_acute_qwerty_win>, <&macro_cap_e_acute_win>;
            mods = <(MOD_LSFT|MOD_RSFT)>;
        };
        e_acute_azerty: e_acute_azerty {
            compatible = "zmk,behavior-mod-morph";
            #binding-cells = <0>;
            bindings = <&kp N2>, <&macro_cap_e_acute>;
            mods = <(MOD_LSFT|MOD_RSFT)>;
        };
        e_acute_azerty_win: e_acute_azerty_win {
            compatible = "zmk,behavior-mod-morph";
            #binding-cells = <0>;
            bindings = <&kp N2>, <&macro_cap_e_acute_win>;
            mods = <(MOD_LSFT|MOD_RSFT)>;
        };


        // è et È
        e_grave_qwerty: e_grave_qwerty {
            compatible = "zmk,behavior-mod-morph";
            #binding-cells = <0>;
            bindings = <&macro_e_grave_qwerty>, <&macro_cap_e_grave>;
            mods = <(MOD_LSFT|MOD_RSFT)>;
        };
        e_grave_qwerty_win: e_grave_qwerty_win {
            compatible = "zmk,behavior-mod-morph";
            #binding-cells = <0>;
            bindings = <&macro_e_grave_qwerty_win>, <&macro_cap_e_grave_win>;
            mods = <(MOD_LSFT|MOD_RSFT)>;
        };
        e_grave_azerty: e_grave_azerty {
            compatible = "zmk,behavior-mod-morph";
            #binding-cells = <0>;
            bindings = <&kp N3>, <&macro_cap_e_grave>;
            mods = <(MOD_LSFT|MOD_RSFT)>;
        };
        e_grave_azerty_win: e_grave_azerty_win {
            compatible = "zmk,behavior-mod-morph";
            #binding-cells = <0>;
            bindings = <&kp N3>, <&macro_cap_e_grave_win>;
            mods = <(MOD_LSFT|MOD_RSFT)>;
        };


        // ê et Ê
        e_circ: e_circ {
            compatible = "zmk,behavior-mod-morph";
            #binding-cells = <0>;
            bindings = <&macro_e_circ>, <&macro_cap_e_circ>;
            mods = <(MOD_LSFT|MOD_RSFT)>;
        };
        e_circ_win: e_circ_win {
            compatible = "zmk,behavior-mod-morph";
            #binding-cells = <0>;
            bindings = <&macro_e_circ_win>, <&macro_cap_e_circ_win>;
            mods = <(MOD_LSFT|MOD_RSFT)>;
        };


        // ñ et Ñ
        n_tilde: n_tilde {
            compatible = "zmk,behavior-mod-morph";
            #binding-cells = <0>;
            bindings = <&macro_n_tilde>, <&macro_cap_n_tilde>;
            mods = <(MOD_LSFT|MOD_RSFT)>;
        };
        n_tilde_win: n_tilde_win {
            compatible = "zmk,behavior-mod-morph";
            #binding-cells = <0>;
            bindings = <&macro_n_tilde_win>, <&macro_cap_n_tilde_win>;
            mods = <(MOD_LSFT|MOD_RSFT)>;
        };


        // ( et none :
// continuer ?





        /////////////////////////////////////////////////////////////////////////////
        // Rangée 4                                                                //
        /////////////////////////////////////////////////////////////////////////////

        // - et ?
        moins_qwerty: moins_p_inter_qwerty {
            compatible = "zmk,behavior-mod-morph";
            #binding-cells = <0>;
            bindings = <&kp MINUS>, <&kp QMARK>;
            mods = <(MOD_LSFT|MOD_RSFT)>;
        };
        moins_azerty: moins_p_inter_azerty {
            compatible = "zmk,behavior-mod-morph";
            #binding-cells = <0>;
            bindings = <&kp N6>, <&kp LS(M)>;
            mods = <(MOD_LSFT|MOD_RSFT)>;
        };


        // . et :
        point_qwerty: point_2_points_qwerty {
            compatible = "zmk,behavior-mod-morph";
            #binding-cells = <0>;
            bindings = <&kp DOT>, <&kp COLON>;
            mods = <(MOD_LSFT|MOD_RSFT)>;
        };
        point_azerty: point_2_points_azerty {
            compatible = "zmk,behavior-mod-morph";
            #binding-cells = <0>;
            bindings = <&kp LS(COMMA)>, <&kp DOT>;
            mods = <(MOD_LSFT|MOD_RSFT)>;
        };


        // , et ;
        virg_qwerty: virgule_p_virg_qwerty {
            compatible = "zmk,behavior-mod-morph";
            #binding-cells = <0>;
            bindings = <&kp COMMA>, <&kp SEMI>;
            mods = <(MOD_LSFT|MOD_RSFT)>;
        };
        virg_azerty: virgule_p_virg_azerty {
            compatible = "zmk,behavior-mod-morph";
            #binding-cells = <0>;
            bindings = <&kp M>, <&kp COMMA>;
            mods = <(MOD_LSFT|MOD_RSFT)>;
        };










        // vérifier s'il reste du ////// Normal ////// et ////// Shift //////
        // il faut aussi faire les behavior pour Symboles et Shift


        // est-ce qu'il vaudrait pas mieux faire plus de layer, une 1DK et
        // une 1DK Shift, une Symboles et une Symboles Shift ?
        // et le modifier change la sticky layer
        // le sticky layer 1dk et shift : faire un toggle/untoggle sur la 
        // touche shift de la layer 1dk en macro
        // permettrait de faire une layer CAPS, et donc de régler le problème
        // shift sur la layer 1dk devient un &mo, ou une macro ?
        // c'est facile d'enlever les behavior en trop

        td0: tap_dance_ergol_conf {
            compatible = "zmk,behavior-tap-dance";
            label = "ERGOL_CONF";
            #binding-cells = <0>;
            tapping-term-ms = <200>;
            bindings = <&to 1>, <&tog 7>;
        };

        td1: tap_dance_qwerty_conf {
            compatible = "zmk,behavior-tap-dance";
            label = "QWERTY_CONF";
            #binding-cells = <0>;
            tapping-term-ms = <200>;
            bindings = <&to 0>, <&tog 7>;
        };


 
        e_trem: e_trem {
            compatible = "zmk,behavior-mod-morph";
            #binding-cells = <0>;
            bindings = <&macro_e_trem>, <&macro_cap_e_trem>;
            mods = <(MOD_LSFT|MOD_RSFT)>;
        };



        a_trem: a_trem {
            compatible = "zmk,behavior-mod-morph";
            #binding-cells = <0>;
            bindings = <&macro_a_trem>, <&macro_cap_a_trem>;
            mods = <(MOD_LSFT|MOD_RSFT)>;
        };

        u_grave: u_grave {
            compatible = "zmk,behavior-mod-morph";
            #binding-cells = <0>;
            bindings = <&macro_u_grave>, <&macro_cap_u_grave>;
            mods = <(MOD_LSFT|MOD_RSFT)>;
        };


        u_trem: u_trem {
            compatible = "zmk,behavior-mod-morph";
            #binding-cells = <0>;
            bindings = <&macro_u_trem>, <&macro_cap_u_trem>;
            mods = <(MOD_LSFT|MOD_RSFT)>;
        };

        i_circ: i_circ {
            compatible = "zmk,behavior-mod-morph";
            #binding-cells = <0>;
            bindings = <&macro_i_circ>, <&macro_cap_i_circ>;
            mods = <(MOD_LSFT|MOD_RSFT)>;
        };

        i_trem: i_trem {
            compatible = "zmk,behavior-mod-morph";
            #binding-cells = <0>;
            bindings = <&macro_i_trem>, <&macro_cap_i_trem>;
            mods = <(MOD_LSFT|MOD_RSFT)>;
        };

        o_circ: o_circ {
            compatible = "zmk,behavior-mod-morph";
            #binding-cells = <0>;
            bindings = <&macro_o_circ>, <&macro_cap_o_circ>;
            mods = <(MOD_LSFT|MOD_RSFT)>;
        };

        o_trem: o_trem {
            compatible = "zmk,behavior-mod-morph";
            #binding-cells = <0>;
            bindings = <&macro_o_trem>, <&macro_cap_o_trem>;
            mods = <(MOD_LSFT|MOD_RSFT)>;
        };

        
    };

    keymap {
        compatible = "zmk,keymap";

        default_layer { // layer 0

            display-name = "qwerty";
            label = "qwerty";

// --------------------------------------------------------------------------------------------------------------------
// | ESC     |  1  |  2  |  3   |  4   |  5   |   | UP_ARROW    |   |  6   |  7    |  8    |  9   |   0   | DELETE    |
// | TAB     |  Q  |  W  |  E   |  R   |  T   |   | DOWN_ARROW  |   |  Y   |  U    |  I    |  O   |   P   | BACKSPACE |
// | CAPS    |  A  |  S  |  D   |  F   |  G   |   | LEFT_ARROW  |   |  H   |  J    |  K    |  L   |   ;   | ENTER     |
// | L_SHIFT |  Z  |  X  |  C   |  V   |  B   |   | RIGHT_ARROW |   |  N   |  M    |  ,    |  .   |   /   | SHIFT     |
// | C_MUTE  |  | L_GUI | L_ALT | NAV | SPACE| L_CTL |  | ENTER |  | R_CTL | SPACE | R_ALT | TD_1_7 | R_GUI |
// | C_VOL_UP ! C_VOL_DN |

            bindings = <
&gresc      &kp N1        &kp N2        &kp N3  &kp N4     &kp N5       &kp UP_ARROW     &kp N6     &kp N7     &kp N8     &kp N9   &kp N0    &kp DELETE
&kp TAB     &kp Q         &kp W         &kp E   &kp R      &kp T        &kp DOWN_ARROW   &kp Y      &kp U      &kp I      &kp O    &kp P     &kp BACKSPACE
&kp CAPS    &kp A         &kp S         &kp D   &kp F      &kp G        &kp LEFT_ARROW   &kp H      &kp J      &kp K      &kp L    &kp SEMI  &kp ENTER
&kp LSHFT   &kp Z         &kp X         &kp C   &kp V      &kp B        &kp RIGHT_ARROW  &kp N      &kp M      &kp COMMA  &kp DOT  &kp FSLH  &kp RIGHT_SHIFT
&kp C_MUTE  &kp LEFT_WIN  &kp LEFT_ALT  &mo 1   &kp SPACE  &kp LCTRL    &kp ENTER        &kp RCTRL  &kp SPACE  &kp RALT   &to 1    &kp RGUI
            >;

            sensor-bindings = <&inc_dec_kp C_VOLUME_UP C_VOL_DN>;
        };
    
        ergol_qwerty { // layer 1

            display-name = "Ergo2qw";  // Ergol sur QWERTY
            label = "Ergo2qw_default";

// --------------------------------------------------------------------------------------------------------------------
// |         | 1/€ | 2 « | 3 »  |      |      |   |             |   |      |       |       |  9 # |  0 @  |           |
// |         |     |  C  |  O   |  P   |  W   |   |             |   |  J   |  U    |  D    | DK ! |   Y   |           |
// | TOG_4   |     |     |  E   |  N   |  F   |   |             |   |  L   |  R    |  T    |  I   |   U   |           |
// |         |     |     |  - ? |      |      |   |             |   | . :  |  H    |  G    |  , ; |   K   |           |
// |      |  |      |      | NAV | SP SP_INSEC |     |  |       |  |      | SP SP_INSEC | MO_CHARS | TD_0_7 |      |       !!!
// | C_VOL_UP ! C_VOL_DN |

            bindings = <
&trans      &euro         &chevron_l    &chevron_r    &trans     &trans       &trans           &trans        &trans     &trans    &sharp       &arob     &trans
&trans      &trans        &kp C         &kp O         &kp P      &kp W        &trans           &kp J         &kp M      &kp D     &dead1       &kp Y     &trans
&tog 4      &trans        &trans        &kp E         &kp N      &kp F        &trans           &kp L         &kp R      &kp T     &kp I        &kp U     &trans
&trans      &trans        &trans        &moins_qwerty &trans     &trans       &trans           &point_qwerty &kp H      &kp G     &virg_qwerty &kp K     &trans
&trans      &trans        &trans        &mo 6         &trans     &trans       &trans           &trans        &trans     &mo 5     &td1         &trans
            >;

            sensor-bindings = <&inc_dec_kp C_VOLUME_UP C_VOL_DN>;
        };


        ergol_qwerty_win { // layer 2

            display-name = "Ergo2qw_win";  // Ergol sur QWERTY Windows
            label = "Ergo2qw_win_default";

// --------------------------------------------------------------------------------------------------------------------
// |         | 1/€ | 2 « | 3 »  |      |      |   |             |   |      |       |       |  9 # |  0 @  |           |
// |         |     |  C  |  O   |  P   |  W   |   |             |   |  J   |  U    |  D    | DK ! |   Y   |           |
// | TOG_4   |     |     |  E   |  N   |  F   |   |             |   |  L   |  R    |  T    |  I   |   U   |           |
// |         |     |     |  - ? |      |      |   |             |   | . :  |  H    |  G    |  , ; |   K   |           |
// |      |  |      |      | NAV | SP SP_INSEC |     |  |       |  |      | SP SP_INSEC | MO_CHARS | TD_0_7 |      |       !!!
// | C_VOL_UP ! C_VOL_DN |

            bindings = <
&trans      &euro         &chevron_l    &chevron_r    &trans     &trans       &trans           &trans        &trans     &trans    &sharp       &arob     &trans
&trans      &trans        &kp C         &kp O         &kp P      &kp W        &trans           &kp J         &kp M      &kp D     &dead1       &kp Y     &trans
&tog 4      &trans        &trans        &kp E         &kp N      &kp F        &trans           &kp L         &kp R      &kp T     &kp I        &kp U     &trans
&trans      &trans        &trans        &moins_qwerty &trans     &trans       &trans           &point_qwerty &kp H      &kp G     &virg_qwerty &kp K     &trans
&trans      &trans        &trans        &mo 6         &trans     &trans       &trans           &trans        &trans     &mo 5     &td1         &trans
            >;

            sensor-bindings = <&inc_dec_kp C_VOLUME_UP C_VOL_DN>;
        };
    
        ergol_azerty { // layer 3

            display-name = "Ergo2az";  // Ergol sur AZERTY
            label = "Ergo2az_default";

// --------------------------------------------------------------------------------------------------------------------
// |         | 1/€ | 2 « | 3 »  |      |      |   |             |   |      |       |       |  9 # |  0 @  |           |
// |         |     |  C  |  O   |  P   |  W   |   |             |   |  J   |  U    |  D    | DK ! |   Y   |           |
// | TOG_4   |     |     |  E   |  N   |  F   |   |             |   |  L   |  R    |  T    |  I   |   U   |           |
// |         |     |     |  - ? |      |      |   |             |   | . :  |  H    |  G    |  , ; |   K   |           |
// |      |  |      |      | NAV | SP SP_INSEC |     |  |       |  |      | SP SP_INSEC | MO_CHARS | TD_0_7 |      |       !!!
// | C_VOL_UP ! C_VOL_DN |

            bindings = <
&trans      &euro         &chevron_l    &chevron_r    &trans     &trans       &trans           &trans        &trans     &trans    &sharp       &arob     &trans
&trans      &trans        &kp C         &kp O         &kp P      &kp W        &trans           &kp J         &kp M      &kp D     &dead1       &kp Y     &trans
&tog 4      &trans        &trans        &kp E         &kp N      &kp F        &trans           &kp L         &kp R      &kp T     &kp I        &kp U     &trans
&trans      &trans        &trans        &moins_azerty &trans     &trans       &trans           &point_azerty &kp H      &kp G     &virg_azerty &kp K     &trans
&trans      &trans        &trans        &mo 6         &trans     &trans       &trans           &trans        &trans     &mo 5     &td1         &trans
            >;

            sensor-bindings = <&inc_dec_kp C_VOLUME_UP C_VOL_DN>;
        };


        ergol_azerty_win { // layer 4

            display-name = "Ergo2az_win";  // Ergol sur AZERTY Windows
            label = "Ergo2az_win_default";

// --------------------------------------------------------------------------------------------------------------------
// |         | 1/€ | 2 « | 3 »  |      |      |   |             |   |      |       |       |  9 # |  0 @  |           |
// |         |     |  C  |  O   |  P   |  W   |   |             |   |  J   |  U    |  D    | DK ! |   Y   |           |
// | TOG_4   |     |     |  E   |  N   |  F   |   |             |   |  L   |  R    |  T    |  I   |   U   |           |
// |         |     |     |  - ? |      |      |   |             |   | . :  |  H    |  G    |  , ; |   K   |           |
// |      |  |      |      | NAV | SP SP_INSEC |     |  |       |  |      | SP SP_INSEC | MO_CHARS | TD_0_7 |      |       !!!
// | C_VOL_UP ! C_VOL_DN |

            bindings = <
&trans      &euro         &chevron_l    &chevron_r    &trans     &trans       &trans           &trans        &trans     &trans    &sharp       &arob     &trans
&trans      &trans        &kp C         &kp O         &kp P      &kp W        &trans           &kp J         &kp M      &kp D     &dead1       &kp Y     &trans
&tog 4      &trans        &trans        &kp E         &kp N      &kp F        &trans           &kp L         &kp R      &kp T     &kp I        &kp U     &trans
&trans      &trans        &trans        &moins_azerty &trans     &trans       &trans           &point_azerty &kp H      &kp G     &virg_azerty &kp K     &trans
&trans      &trans        &trans        &mo 6         &trans     &trans       &trans           &trans        &trans     &mo 5     &td1         &trans
            >;

            sensor-bindings = <&inc_dec_kp C_VOLUME_UP C_VOL_DN>;
        };


        dead_1k_layer { // layer 2

            label = "Ergo2qw_1dk";
            display-name = "Ergo2qw_1dk";

// --------------------------------------------------------------------------------------------------------------
// |         |      | “ !! | ” !! |      |      |   |         |   |      |       |       |      |       |         |    !!!
// |         |  â   |  ç   | œ !! |   ô  |      |   |         |   |      |       |   _   |  ¨   |   û   |         |    !!!
// |         |  à   |  é   |  è   |   ê  |      |   |         |   |   (  |    )  |   î   |  ï   |   ù   |         |
// |         | æ !! |      | ‑ !! | – !! | — !! |   |         |   | … !! |       |       |      |       |         |    !!!
// |      |  |      |      |      |      |      |   |         |   |      |       |       |      |       |
// | C_VOL_UP ! C_VOL_DN |
    
            bindings = <
&trans      &trans     &trans     &trans       &trans     &trans    &trans   &trans    &trans   &trans    &trans     &trans    &trans
&trans      &a_circ    &c_cedi    &trans       &o_circ    &trans    &trans   &trans    &trans   &kp UNDER &sl 3      &u_circ    &trans
&trans      &a_grave   &e_acute    &e_grave     &e_circ    &trans    &trans   &kp LPAR  &kp RPAR &i_circ   &i_trem    &u_grave  &trans
&trans      &trans     &trans     &trans       &trans     &trans    &trans   &trans    &trans   &trans    &trans     &trans    &trans
&trans      &trans     &trans     &trans       &trans     &trans    &trans   &trans    &trans   &trans    &trans     &trans
            >;

            sensor-bindings = <&inc_dec_kp C_VOLUME_UP C_VOL_DN>;
        };

        dead_2k_layer { // layer 3

            label = "Ergo2qw_2dk";
            display-name = "Ergo2qw_2dk";

// --------------------------------------------------------------------------------------------------------------
// |         |     |     |      |      |      |   |         |   |      |       |       |      |       |         |   
// |         |     |     |  ö   |      |      |   |         |   |      |       |       |  "   | ÿ !!  |         |   !!!
// |         |  ä  |     |  ë   |      |      |   |         |   |      |       |       |  ï   |   ü   |         |
// |         |     |     |      |      |      |   |         |   |      |       |       |      |       |         |
// |      |  |     |     |      | ¨ !! |     |   |        |   |      | ¨ !!  |       |      |       |               !!!   " et pas trema !! 
// | C_VOL_UP ! C_VOL_DN |
    
            bindings = <
&trans  &trans    &trans   &trans    &trans     &trans    &trans   &trans   &trans     &trans    &trans     &trans    &trans
&trans  &trans    &trans   &o_trem   &trans     &trans    &trans   &trans   &trans     &trans    &kp DQT    &trans    &trans
&trans  &a_trem   &trans   &e_trem   &trans     &trans    &trans   &trans   &trans     &trans    &i_trem    &u_trem   &trans
&trans  &trans    &trans   &trans    &trans     &trans    &trans   &trans   &trans     &trans    &trans     &trans    &trans
&trans  &trans    &trans   &trans    &macro_dqt &trans    &trans   &trans   &macro_dqt &trans    &trans     &trans
            >;

            sensor-bindings = <&inc_dec_kp C_VOLUME_UP C_VOL_DN>;
        };

        caps_layer { // layer 4 

            label = "Ergo2qw_caps";
            display-name = "Ergo2qw_caps";

// --------------------------------------------------------------------------------------------------------------
// |   NONE  |  1  |  2  |  3   |      |      |   |         |   |      |       |       |  8   |   9   |         |
// |         |     |     |      |      |      |   |         |   |      |       |       |      |       |         |
// |  TOG_4  |     |     |      |      |      |   |         |   |      |       |       |      |       |         |
// |         |     |     |      |      |      |   |         |   |      |       |       |      |       |         |
// |      |  |     |     |      |      |      |   |         |   |      |       |       |      |       |
// | C_VOL_UP ! C_VOL_DN |
    
            bindings = <
&none       &kp N1     &kp N2     &kp N3       &trans     &trans    &trans   &trans       &trans     &trans    &kp N9     &kp N0    &trans
&trans      &trans     &trans     &trans       &trans     &trans    &trans   &trans       &trans     &trans    &trans     &trans    &trans
&tog 4      &trans     &trans     &trans       &trans     &trans    &trans   &trans       &trans     &trans    &trans     &trans    &trans
&trans      &trans     &trans     &trans       &trans     &trans    &trans   &trans       &trans     &trans    &trans     &trans    &trans
&trans      &trans     &trans     &trans       &trans     &trans    &trans   &trans       &trans     &trans    &trans     &trans
            >;

            sensor-bindings = <&inc_dec_kp C_VOLUME_UP C_VOL_DN>;
        };

        chars_layer { // layer 5

            label = "Ergo2qw_chars";
            display-name = "Ergo2qw_chars";

// --------------------------------------------------------------------------------------------------------------
// |         |     |     |      |      |      |   |         |   |      |       |       |      |       |         |   indices !!!
// |         |  ^  |  <  |  >   |   $  |   %  |   |         |   |   @  |   &   |   *   |  '   |   `   |         |   
// |         |  {  |  (  |  )   |   }  |   =  |   |         |   |   \  |   +   |   -   |  /   |   "   |         |
// |         |  ~  |  [  |  ]   |   _  |   #  |   |         |   |   |  |   !   |   ;   |  :   |   ?   |         |
// |      |  |     |     |      |      |      |   |         |   |      |       |       |      |       |
// | C_VOL_UP ! C_VOL_DN |
    
            bindings = <
&trans      &trans       &trans        &trans       &trans     &trans     &trans   &trans       &trans     &trans     &trans     &trans       &trans
&trans      &macro_caret &kp LT        &kp GT       &kp DLLR   &kp PRCNT  &trans   &kp AT       &kp AMPS   &kp STAR   &macro_sqt &macro_grave &trans
&trans      &kp LBRC     &kp LPAR      &kp RPAR     &kp RBRC   &kp EQUAL  &trans   &kp BSLH     &kp PLUS   &kp MINUS  &kp FSLH   &macro_dqt   &trans
&trans      &kp TILDE    &kp LBKT      &kp RBKT     &kp UNDER  &kp HASH   &trans   &kp PIPE     &kp EXCL   &kp SEMI   &kp COLON  &kp QMARK    &trans
&trans      &trans       &trans        &trans       &trans     &trans     &trans   &trans       &trans     &trans     &trans     &trans
            >;

            sensor-bindings = <&inc_dec_kp C_VOLUME_UP C_VOL_DN>;
        };
        
        nav_fn_kp_layer { // layer 6 
            
            display-name = "Fn-Nav-KP";
            label = "Fn-Nav-KP";
            
            bindings = <
&kp GRAVE   &kp F1           &kp F2          &kp F3          &kp F4           &kp F5             &mmv MOVE_UP     &kp F6        &kp F7     &kp F8     &kp F9     &kp F10         &kp F11
&trans      &kp INS          &kp HOME        &kp UP_ARROW    &kp END          &kp PG_UP          &mmv MOVE_DOWN   &kp KP_SLASH  &kp KP_N7  &kp KP_N8  &kp KP_N9  &kp KP_MULTIPLY &kp F12
&trans      &kp PSCRN        &kp LEFT_ARROW  &kp DOWN_ARROW  &kp RIGHT_ARROW  &kp PG_DN          &mmv MOVE_LEFT   &kp KP_MINUS  &kp KP_N4  &kp KP_N5  &kp KP_N6  &kp KP_N0       &trans
&trans      &none            &kp C_VOL_DN    &kp C_MUTE      &kp C_VOLUME_UP  &none              &mmv MOVE_RIGHT  &kp KP_PLUS   &kp KP_N1  &kp KP_N2  &kp KP_N3  &kp KP_DOT      &trans
&kp C_MUTE  &trans           &trans          &trans          &trans           &trans             &mkp LCLK        &trans        &trans     &trans     &trans     &trans
            >;

            sensor-bindings = <&scroll_encoder>;
        };

        config_layer { // layer 7 
            display-name = "config";
            label = "config";
            
            bindings = <
&soft_off    &bt BT_SEL 0  &bt BT_SEL 1    &bt BT_SEL 2  &bt BT_SEL 3  &bt BT_SEL 4    &trans       &trans          &trans           &trans           &trans  &trans  &soft_off
&sys_reset   &bt BT_CLR    &bt BT_CLR_ALL  &trans        &trans        &trans          &trans       &trans          &trans           &trans           &trans  &trans  &sys_reset
&bootloader  &out OUT_USB  &out OUT_BLE    &trans        &trans        &trans          &trans       &trans          &trans           &trans           &trans  &trans  &bootloader
&trans       &trans        &trans          &bootloader   &trans        &trans          &trans       &rgb_ug RGB_ON  &rgb_ug RGB_OFF  &rgb_ug RGB_EFF  &trans  &trans  &trans
&trans       &trans        &trans          &trans        &trans        &trans          &trans       &trans          &trans           &trans           &tog 7  &trans
            >;

            sensor-bindings = <&scroll_encoder>;
        };

    };
};
